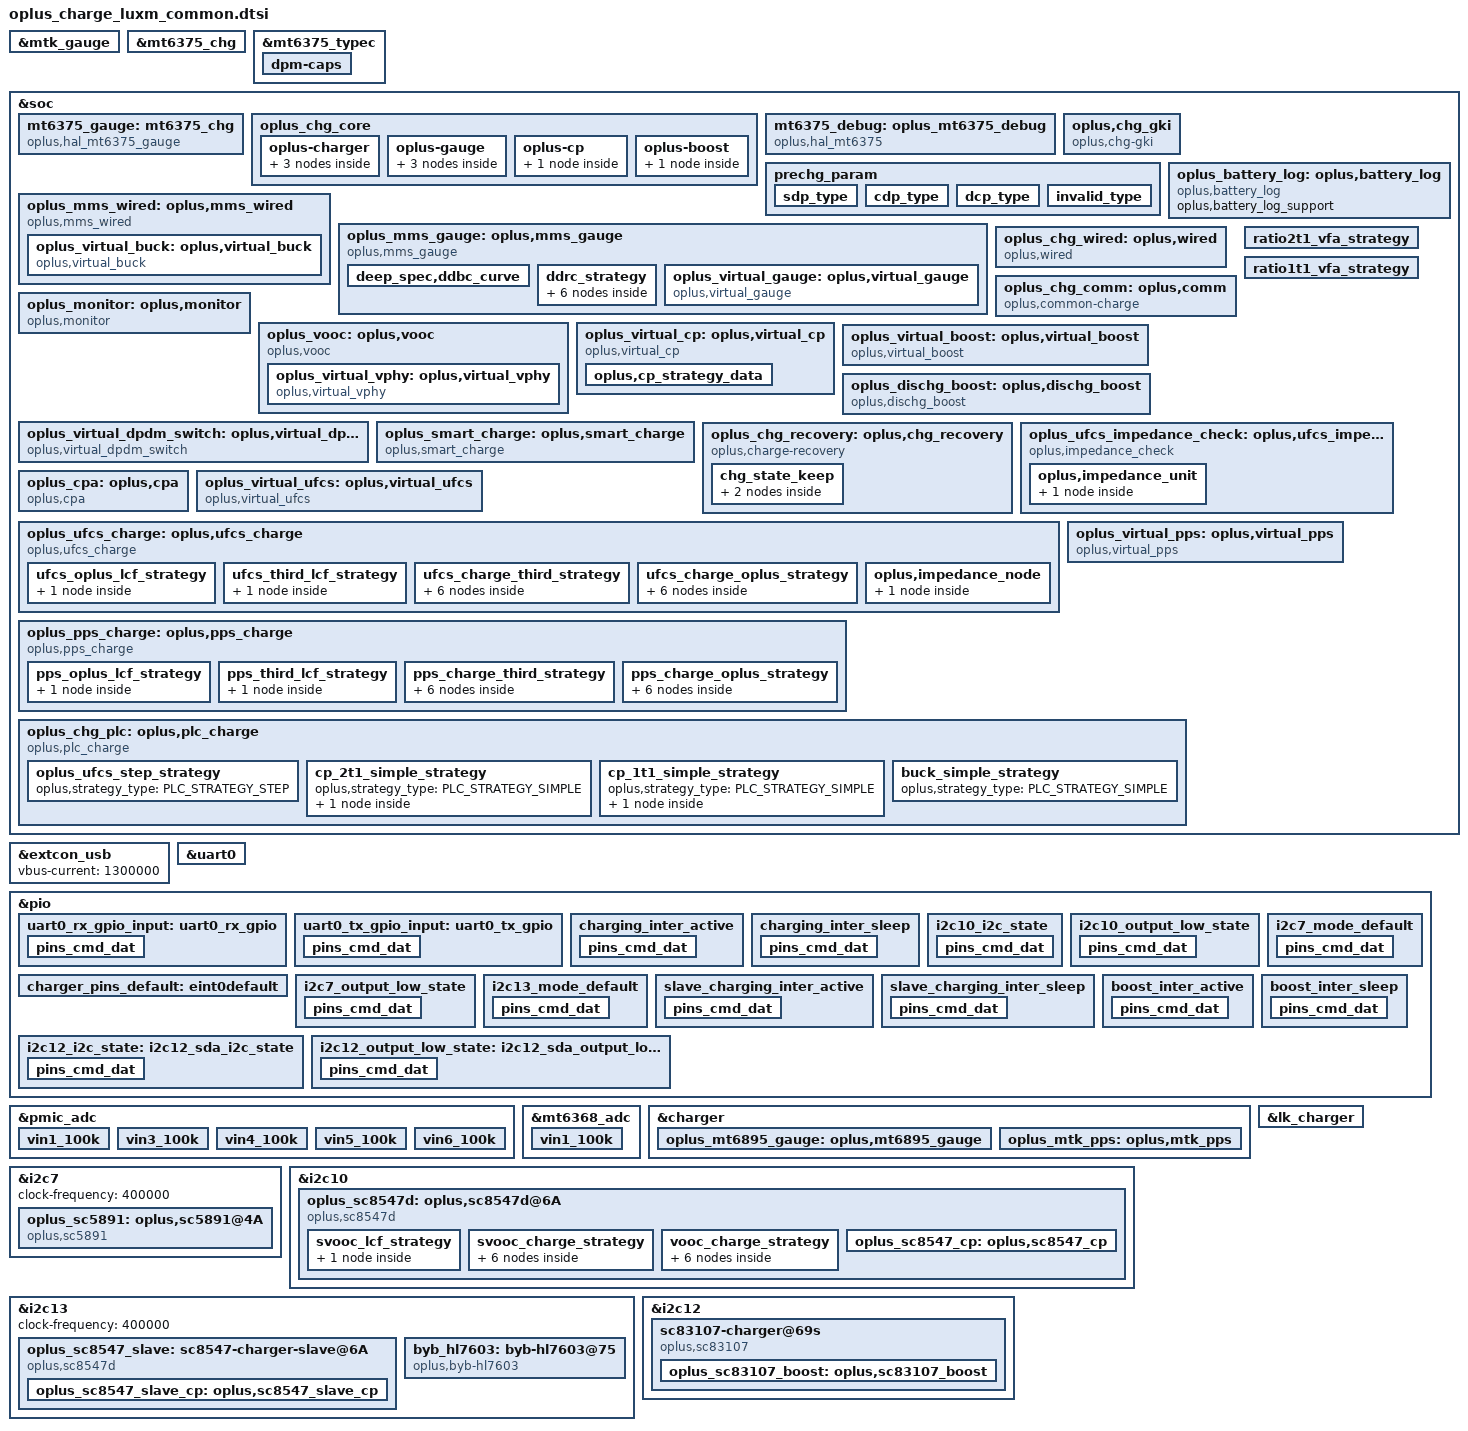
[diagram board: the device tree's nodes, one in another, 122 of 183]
// SPDX-License-Identifier: GPL-2.0-only
/*
* Copyright (C) 2025 Oplus. All rights reserved.
*/
#include <dt-bindings/iio/mt635x-auxadc.h>
#include <dt-bindings/pinctrl/mt6373-pinfunc.h>
#include <dt-bindings/pinctrl/mt65xx.h>
#include <dt-bindings/mfd/mt6375.h>
#include <dt-bindings/iio/adc/mediatek,mt6375_auxadc.h>
#include <dt-bindings/iio/adc/mediatek,mt6375_adc.h>
#include "oplus_chg.h"

&mtk_gauge {
	status = "okay";
	charger = <&mt6375_chg>;
	FUELGAGUE_APPLY = <(1)>;
	IS_SUBBOARD_TEMP_SUPPORT = <(0)>;
	EXTERNAL_AUTHENTICATE =<(1)>;
	Enable_Is_Force_Full = <(1)>;

	active-table = <(5)>;
	r-fg-value = <(1)>; /* R_sense resistance. evb1 use 2; evb2 and later use 1 milliohm */
	com-r-fg-value = <(0)>; /* R_sense compensate resistance. not use COM_R_FG_VALUE */
	RBAT_PULL_DOWN_R = <(24000)>;
	RBAT_PULL_UP_R = <(12000)>;
	RBAT_PULL_UP_VOLT = <(2800)>;
	USE_MORE_PRECISE_NTC_TABLE = <(1)>;
	car-tune-value = <(100)>;
	BAT_VOLTAGE_LOW_BOUND =  <(2750)>;
	LOW_TMP_BAT_VOLTAGE_LOW_BOUND =  <(2850)>;
	SHUTDOWN_GAUGE1_VBAT = <(27500)>;
	shutdown-gauge0-voltage = <(27500)>;
	VBAT2_DET_VOLTAGE1 = <(28000)>;
	VBAT2_DET_VOLTAGE2 = <(26000)>;
	VBAT2_DET_VOLTAGE3 = <(28500)>;
	SHUTDOWN_1_TIME = <(60)>;
	DIM2_TABLE_DISTINGUISH = <(1)>;
	AGING_FACTOR_MIN = <(75)>;
	BAT_BH_EN = <(1)>;
	keep-100-percent-minsoc = <(9500)>;
	aging-factor-diff = <(1)>;
	keep-100-percent = <(2)>;

	/* compensate The resistance of PCB */
	com-fg-meter-resistance = <(-20)>;
	#include "bat_setting/mt6899_battery_prop_dim2_ext_luxm.dtsi"
	#include "bat_setting/mt6899_battery_table_luxm.dtsi"
};

&mt6375_chg {
	interrupts = <MT6375_FL_PWR_RDY>, <MT6375_FL_DETACH>,
				<MT6375_FL_VBUS_OV>, <MT6375_FL_CHG_TOUT>,
				<MT6375_FL_WDT>, <MT6375_FL_BC12_DN>,
				<MT6375_INT_CHRDET_EXT>,
				<MT6375_FL_AICC_DONE>, <MT6375_FL_PE_DONE>,
				<MT6375_FL_BATPRO_DONE>,
				<MT6375_ADC_VBAT_MON_OV>,
				<MT6375_USBID_EVT>;
	interrupt-names = "fl_pwr_rdy", "fl_detach",
				"fl_vbus_ov", "fl_chg_tout",
				"fl_wdt", "fl_bc12_dn",
				"int_chrdet_ext",
				"fl_aicc_done", "fl_pe_done",
				"fl_batpro_done", "adc_vbat_mon_ov",
				"usbid_evt";
};

&mt6375_typec {
	/* 0: Unknown, 1: SNK, 2: SRC, 3: DRP, 4: Try.SRC, 5: Try.SNK */
	tcpc,role-def = <1>;
	/* 0: Default, 1: 1.5, 2: 3.0 */
	tcpc,rp-level = <0>;

	tcpc,en-floatgnd;
	wd,wd0-tsleep = <0>; /* add for wd0 */

	dpm-caps {
		attempt-discover-cable;
		/* BSP.CHG.Basic add for pd_svooc */
		/* add for tcpc */
		attempt-discover-id;
		attempt-discover-svids;
	};
};

&soc {
	mt6375_gauge: mt6375_chg {
		status = "okay";
		compatible = "oplus,hal_mt6375_gauge";

		oplus,ic_type = <OPLUS_CHG_IC_GAUGE>;
		oplus,ic_index = <1>;
		oplus,batt_num = <1>;
		oplus,mtk_gauge_power_sel_support;
		oplus,mtk_gauge_cali_track_support;
		oplus,mtk_gauge_power_sel_by_power_support;
		/* graphite sub btb valid temperature range, which is provided by hardware engineer. */
		oplus,sub_btb_valid_temp = <(-350) 1000>;

		oplus,vbatt_full_cv = <44500>;
		oplus,term_vol_temp_range = <350 200 100 0 (-100)>;
		oplus,term_vol_base = <27500 27500 27500 29000 30000 30000>;
	};
};

&extcon_usb {
	vbus-current = <1300000>;
};

&uart0 {
	pinctrl-names = "uart0_rx_gpio", "uart0_tx_gpio";
	pinctrl-0 = <&uart0_rx_gpio_input>;
	pinctrl-1 = <&uart0_tx_gpio_input>;
	status = "okay";
	txpin = <207>;
	rxpin = <208>;
};

&pio {
	uart0_rx_gpio_input: uart0_rx_gpio {
		pins_cmd_dat {
			pinmux = <PINMUX_GPIO208__FUNC_GPIO208>; /* URXD0 */
			input-enable;
			bias-disable;
		};
	};

	uart0_tx_gpio_input: uart0_tx_gpio {
		pins_cmd_dat {
			pinmux = <PINMUX_GPIO207__FUNC_GPIO207>; /* UTXD0 */
			input-enable;
			bias-disable;
		};
	};
};

&pmic_adc {
	vin1_100k {
		channel = <AUXADC_VIN1>;
		pures = <ADC_PURES_100K>;
	};
	vin3_100k {
		channel = <AUXADC_VIN3>;
		pures = <ADC_PURES_100K>;
	};
	vin4_100k {
		channel = <AUXADC_VIN4>;
		pures = <ADC_PURES_100K>;
	};
	vin5_100k {
		channel = <AUXADC_VIN5>;
		pures = <ADC_PURES_100K>;
	};
	vin6_100k {
		channel = <AUXADC_VIN6>;
		pures = <ADC_PURES_100K>;
	};
};

&mt6368_adc {
	vin1_100k {
		channel = <AUXADC_VIN1>;
		pures = <ADC_PURES_100K>;
	};
};

&pio {
	charging_inter_active: charging_inter_active {
		pins_cmd_dat {
			pinmux = <PINMUX_GPIO40__FUNC_GPIO40>;
			input-enable;
			bias-pull-up;
		};
	};

	charging_inter_sleep: charging_inter_sleep {
		pins_cmd_dat {
			pinmux = <PINMUX_GPIO40__FUNC_GPIO40>;
			input-enable;
			bias-pull-up;
		};
	};

	i2c10_i2c_state: i2c10_i2c_state {
		pins_cmd_dat {
			pinmux = <PINMUX_GPIO33__FUNC_SCL10>,
				 <PINMUX_GPIO34__FUNC_SDA10>;
			bias-disable;
		};
	};

	i2c10_output_low_state: i2c10_output_low_state {
		pins_cmd_dat {
			pinmux = <PINMUX_GPIO33__FUNC_GPIO33>,
				 <PINMUX_GPIO34__FUNC_GPIO34>;
			output-low;
		};
	};

	charger_pins_default: eint0default {
	};
};

&soc {
	oplus_chg_core {
		oplus,chg_framework_v2;
		oplus,smart_charging_screenoff;
		oplus,chg_spec_version = <OPLUS_CHG_SPEC_VER_V3P7_1>;
		oplus,common-charge-icl-support;

		oplus-charger {
			mtk_6895_groups: oplus,mtk_6895-groups {
				functions = <
					OPLUS_IC_FUNC_INIT
					OPLUS_IC_FUNC_EXIT
					OPLUS_IC_FUNC_REG_DUMP
					OPLUS_IC_FUNC_SMT_TEST
					OPLUS_IC_FUNC_BUCK_INPUT_PRESENT
					OPLUS_IC_FUNC_BUCK_INPUT_SUSPEND
					OPLUS_IC_FUNC_BUCK_INPUT_IS_SUSPEND
					OPLUS_IC_FUNC_BUCK_OUTPUT_SUSPEND
					OPLUS_IC_FUNC_BUCK_OUTPUT_IS_SUSPEND
					OPLUS_IC_FUNC_BUCK_SET_ICL
					OPLUS_IC_FUNC_BUCK_GET_ICL
					OPLUS_IC_FUNC_BUCK_SET_FCC
					OPLUS_IC_FUNC_BUCK_SET_FV
					OPLUS_IC_FUNC_BUCK_SET_ITERM
					OPLUS_IC_FUNC_BUCK_GET_INPUT_CURR
					OPLUS_IC_FUNC_BUCK_GET_INPUT_VOL
					OPLUS_IC_FUNC_OTG_BOOST_ENABLE
					OPLUS_IC_FUNC_BUCK_GET_CC_ORIENTATION
					OPLUS_IC_FUNC_BUCK_GET_CHARGER_TYPE
					OPLUS_IC_FUNC_BUCK_RERUN_BC12
					OPLUS_IC_FUNC_BUCK_QC_DETECT_ENABLE
					OPLUS_IC_FUNC_BUCK_SET_QC_CONFIG
					OPLUS_IC_FUNC_BUCK_SET_PD_CONFIG
					OPLUS_IC_FUNC_GET_SHUTDOWN_SOC
					OPLUS_IC_FUNC_BACKUP_SOC
					OPLUS_IC_FUNC_GET_TYPEC_MODE
					OPLUS_IC_FUNC_SET_TYPEC_MODE
					OPLUS_IC_FUNC_GET_TYPEC_ROLE
					OPLUS_IC_FUNC_GET_OTG_ENABLE
					OPLUS_IC_FUNC_BUCK_GET_HW_DETECT
					OPLUS_IC_FUNC_SET_USB_DISCHG_ENABLE
					OPLUS_IC_FUNC_GET_USB_DISCHG_STATUS
					OPLUS_IC_FUNC_IS_OPLUS_SVID
					OPLUS_IC_FUNC_BUCK_GET_USB_BTB_TEMP
					OPLUS_IC_FUNC_BUCK_GET_BATT_BTB_TEMP
					OPLUS_IC_FUNC_BUCK_SHIPMODE_ENABLE
					OPLUS_IC_FUNC_BUCK_SET_AICL_POINT
					OPLUS_IC_FUNC_SET_OTG_BOOST_CURR_LIMIT
					OPLUS_IC_FUNC_SET_OTG_BOOST_VOL
					OPLUS_IC_FUNC_BUCK_GET_FV
					OPLUS_IC_FUNC_BUCK_GET_TYPEC_STATE
					OPLUS_IC_FUNC_BUCK_DIS_INSERT_DETECT
					OPLUS_IC_FUNC_BUCK_GET_USB_AICL_ENHANCE
					OPLUS_IC_FUNC_BUCK_GET_LPD_INFO
					OPLUS_IC_FUNC_BUCK_GET_VBAT_PWR
				>;
				virqs = <
					OPLUS_IC_VIRQ_ERR
					OPLUS_IC_VIRQ_CC_DETECT
					OPLUS_IC_VIRQ_PLUGIN
					OPLUS_IC_VIRQ_CC_CHANGED
					OPLUS_IC_VIRQ_CHG_TYPE_CHANGE
					OPLUS_IC_VIRQ_OTG_ENABLE
					OPLUS_IC_VIRQ_SVID
					OPLUS_IC_VIRQ_TYPEC_STATE
				>;
			};

			mt6375_debug_groups: oplus,mt6375_debug_groups {
				functions = <
					OPLUS_IC_FUNC_INIT
					OPLUS_IC_FUNC_EXIT
				>;
				virqs = <
					OPLUS_IC_VIRQ_ERR
				>;
			};

			byb_hl7603_groups: oplus,byb-hl7603-groups {
				functions = <
					OPLUS_IC_FUNC_INIT
					OPLUS_IC_FUNC_EXIT
					OPLUS_IC_FUNC_REG_DUMP
					OPLUS_IC_FUNC_BUCK_GET_BYB_STATUS
					OPLUS_IC_FUNC_BUCK_GET_BYB_VOUT
					OPLUS_IC_FUNC_BUCK_SET_BYB_VOUT
				>;
				virqs = <
					OPLUS_IC_VIRQ_ERR
				>;
			};
		};

		oplus-gauge {
			mt6375_gauge_groups: oplus,mt6375_gauge_groups {
				functions = <
					OPLUS_IC_FUNC_INIT
					OPLUS_IC_FUNC_EXIT
					OPLUS_IC_FUNC_REG_DUMP
					OPLUS_IC_FUNC_SMT_TEST
					OPLUS_IC_FUNC_GAUGE_GET_BATT_VOL
					OPLUS_IC_FUNC_GAUGE_GET_BATT_MAX
					OPLUS_IC_FUNC_GAUGE_GET_BATT_MIN
					OPLUS_IC_FUNC_GAUGE_GET_BATT_CURR
					OPLUS_IC_FUNC_GAUGE_GET_BATT_TEMP
					OPLUS_IC_FUNC_GAUGE_GET_BATT_SOC
					OPLUS_IC_FUNC_GAUGE_GET_BATT_FCC
					OPLUS_IC_FUNC_GAUGE_GET_BATT_CC
					OPLUS_IC_FUNC_GAUGE_GET_BATT_RM
					OPLUS_IC_FUNC_GAUGE_GET_BATT_SOH
					OPLUS_IC_FUNC_GAUGE_GET_BATT_AUTH
					OPLUS_IC_FUNC_GAUGE_SET_BATT_FULL
					OPLUS_IC_FUNC_GAUGE_UPDATE_DOD0
					OPLUS_IC_FUNC_GAUGE_UPDATE_SOC_SMOOTH
					OPLUS_IC_FUNC_GAUGE_GET_CB_STATUS
					OPLUS_IC_FUNC_GAUGE_GET_BATT_NUM
					OPLUS_IC_FUNC_GAUGE_GET_DEVICE_TYPE
					OPLUS_IC_FUNC_GAUGE_GET_DEVICE_TYPE_FOR_VOOC
					OPLUS_IC_FUNC_GAUGE_GET_BATT_FCC
					OPLUS_IC_FUNC_GAUGE_GET_BATT_FC
					OPLUS_IC_FUNC_GAUGE_GET_BATT_QM
					OPLUS_IC_FUNC_GAUGE_GET_BATT_PD
					OPLUS_IC_FUNC_GAUGE_GET_BATT_RCU
					OPLUS_IC_FUNC_GAUGE_GET_BATT_RCF
					OPLUS_IC_FUNC_GAUGE_GET_BATT_FCU
					OPLUS_IC_FUNC_GAUGE_GET_BATT_FCF
					OPLUS_IC_FUNC_GAUGE_GET_BATT_SOU
					OPLUS_IC_FUNC_GAUGE_GET_BATT_DO0
					OPLUS_IC_FUNC_GAUGE_GET_BATT_DOE
					OPLUS_IC_FUNC_GAUGE_GET_BATT_TRM
					OPLUS_IC_FUNC_GAUGE_GET_BATT_PC
					OPLUS_IC_FUNC_GAUGE_GET_BATT_QS
					OPLUS_IC_FUNC_GAUGE_IS_SUSPEND
					OPLUS_IC_FUNC_GAUGE_GET_BCC_PARMS
					OPLUS_IC_FUNC_GAUGE_FASTCHG_UPDATE_BCC_PARMS
					OPLUS_IC_FUNC_GAUGE_GET_PREV_BCC_PARMS
					OPLUS_IC_FUNC_GAUGE_SET_BCC_PARMS
					OPLUS_IC_FUNC_GAUGE_SET_PROTECT_CHECK
					OPLUS_IC_FUNC_GAUGE_GET_AFI_UPDATE_DONE
					OPLUS_IC_FUNC_GAUGE_CHECK_RESET
					OPLUS_IC_FUNC_GAUGE_GET_DEVICE_TYPE_FOR_BCC
					OPLUS_IC_FUNC_GAUGE_SET_RESET_GAUGE_DATE
					OPLUS_IC_FUNC_GAUGE_GET_DOD0
					OPLUS_IC_FUNC_GAUGE_GET_DOD0_PASSED_Q
					OPLUS_IC_FUNC_GAUGE_GET_QMAX
					OPLUS_IC_FUNC_GAUGE_GET_QMAX_PASSED_Q
					OPLUS_IC_FUNC_GAUGE_SET_BATTERY_CURVE
					OPLUS_IC_FUNC_GAUGE_GET_GAUGE_CAR_C
					OPLUS_IC_FUNC_GAUGE_GET_SUB_BTB_CONNECT_STATE
					OPLUS_IC_FUNC_GAUGE_GET_GAUGE_TYPE
					OPLUS_IC_FUNC_GAUGE_GET_DEC_FG_TYPE
					OPLUS_IC_FUNC_GAUGE_SET_VCT
					OPLUS_IC_FUNC_GAUGE_SYNC_PLUGIN
					OPLUS_IC_FUNC_GAUGE_SET_DEEP_TERM_VOLT
				>;
				virqs = <
					OPLUS_IC_VIRQ_ERR
					OPLUS_IC_VIRQ_OFFLINE
					OPLUS_IC_VIRQ_RESUME
				>;
			};

			mt6895_gauge_groups: oplus,mt6895_gauge_groups {
				functions = <
					OPLUS_IC_FUNC_INIT
					OPLUS_IC_FUNC_EXIT
					OPLUS_IC_FUNC_GAUGE_GET_SUBBOARD_TEMP
				>;
				virqs = <
					OPLUS_IC_VIRQ_ERR
				>;
			};

			sc5891_gauge_groups: oplus,sc5891_gauge_groups {
				functions = <
					OPLUS_IC_FUNC_INIT
					OPLUS_IC_FUNC_EXIT
					OPLUS_IC_FUNC_GAUGE_GET_BATT_HMAC
					OPLUS_IC_FUNC_GAUGE_SEC_GET_ROMID
					OPLUS_IC_FUNC_GAUGE_SEC_WRITE_PAGE
					OPLUS_IC_FUNC_GAUGE_SEC_READ_PAGE
					OPLUS_IC_FUNC_GAUGE_SEC_ECDSA
					OPLUS_IC_FUNC_GAUGE_SEC_ECW
					OPLUS_IC_FUNC_GAUGE_SEC_SHUTDOWN
					OPLUS_IC_FUNC_GAUGE_SET_VCT
					OPLUS_IC_FUNC_GAUGE_GET_VCT
					OPLUS_IC_FUNC_GAUGE_GET_DEEP_DISCHG_COUNT
					OPLUS_IC_FUNC_GAUGE_SET_DEEP_DISCHG_COUNT
					OPLUS_IC_FUNC_GAUGE_SET_LAST_CC
					OPLUS_IC_FUNC_GAUGE_GET_LAST_CC
					OPLUS_IC_FUNC_GAUGE_SET_DEEP_TERM_VOLT
					OPLUS_IC_FUNC_GAUGE_GET_DEEP_TERM_VOLT
					OPLUS_IC_FUNC_GAUGE_GET_BATT_AUTH
					OPLUS_IC_FUNC_GAUGE_SEC_SET_PRIKEY
					OPLUS_IC_FUNC_GAUGE_SEC_GET_PRIKEY_INDEX
					OPLUS_IC_FUNC_GAUGE_GET_BATT_SN
					OPLUS_IC_FUNC_GAUGE_GET_SN_MATCH
					OPLUS_IC_FUNC_GAUGE_GET_BATT_HISTSOH_DATA
					OPLUS_IC_FUNC_GAUGE_SET_BATT_HISTSOH_DATA
					OPLUS_IC_FUNC_GAUGE_GET_BATT_IC_SN
					OPLUS_IC_FUNC_GAUGE_GET_DEC_CV_SOH
				>;
				virqs = <
					OPLUS_IC_VIRQ_ERR
				>;
			};
		};

		oplus-cp {
			sc8547_cp_groups: oplus,cp_groups {
			functions = <
					OPLUS_IC_FUNC_INIT
					OPLUS_IC_FUNC_EXIT
					OPLUS_IC_FUNC_REG_DUMP
					OPLUS_IC_FUNC_SMT_TEST
					OPLUS_IC_FUNC_CP_ENABLE
					OPLUS_IC_FUNC_CP_HW_INTI
					OPLUS_IC_FUNC_CP_SET_WORK_START
					OPLUS_IC_FUNC_CP_CHECK_WORK_MODE_SUPPORT
					OPLUS_IC_FUNC_CP_SET_WORK_MODE
					OPLUS_IC_FUNC_CP_GET_WORK_MODE
					OPLUS_IC_FUNC_CP_GET_VIN
					OPLUS_IC_FUNC_CP_GET_IIN
					OPLUS_IC_FUNC_CP_SET_IIN
					OPLUS_IC_FUNC_CP_GET_VOUT
					OPLUS_IC_FUNC_CP_GET_IOUT
					OPLUS_IC_FUNC_CP_GET_VAC
					OPLUS_IC_FUNC_CP_GET_WORK_STATUS
					OPLUS_IC_FUNC_CP_SET_ADC_ENABLE
					OPLUS_IC_FUNC_CP_WATCHDOG_ENABLE
					OPLUS_IC_FUNC_CP_SET_UCP_DISABLE
					OPLUS_IC_FUNC_CP_GET_IIN_MAX
					OPLUS_IC_FUNC_CP_WATCHDOG_RESET
					OPLUS_IC_FUNC_CP_SET_SSTIMEOUT_UCP_ENABLE
				>;
				virqs = <
					OPLUS_IC_VIRQ_ERR
					OPLUS_IC_VIRQ_ONLINE
					OPLUS_IC_VIRQ_OFFLINE
				>;
			};
		};

		oplus-boost {
			sc83107_boost_groups: oplus,boost_groups {
				functions = <
					OPLUS_IC_FUNC_INIT
					OPLUS_IC_FUNC_EXIT
					OPLUS_IC_FUNC_REG_DUMP
					OPLUS_IC_FUNC_SMT_TEST
					OPLUS_IC_FUNC_BOOST_SET_CV
					OPLUS_IC_FUNC_BOOST_ENABLE_OTG_MODE
					OPLUS_IC_FUNC_BOOST_SET_WORK_MODE
					OPLUS_IC_FUNC_BOOST_SET_BCL_RATE
					OPLUS_IC_FUNC_BOOST_SET_BCL_VOL
					OPLUS_IC_FUNC_BOOST_GET_IN_CV_MODE
					OPLUS_IC_FUNC_BOOST_GET_CV
					OPLUS_IC_FUNC_BOOST_IS_SUSPEND
					OPLUS_IC_FUNC_BOOST_SET_SUSPEND_RESUME_CV
				>;
				virqs = <
					OPLUS_IC_VIRQ_ERR
					OPLUS_IC_VIRQ_ONLINE
					OPLUS_IC_VIRQ_OFFLINE
				>;
			};
		};
	};
};

&soc {
	mt6375_debug: oplus_mt6375_debug {
		status = "okay";
		compatible = "oplus,hal_mt6375";

		oplus,tcpc_name = "type_c_port0";

		oplus,ic_type = <OPLUS_CHG_IC_BUCK>;
		oplus,ic_index = <2>;
	};
};

&soc {
	oplus,chg_gki {
		compatible = "oplus,chg-gki";
	};
};

&charger {
	io-channels = <&mt6368_adc (ADC_PURES_100K_MASK | AUXADC_VIN1)>,
		      <&pmic_adc AUXADC_VIN5>,
		      <&pmic_adc AUXADC_VIN5>,
		      <&pmic_adc AUXADC_VIN6>,
		      <&pmic_adc AUXADC_VIN1>,
		      <&pmic_adc AUXADC_VIN5>,
		      <&pmic_adc AUXADC_VIN6>,
			  <&mt6375_adc MT6375_ADC_VBAT>;
	io-channel-names = "auxadc1-ntc_sub_bat_tem",
			   "auxadc5-chargeric_temp",
			   "auxadc5_batt_btb_temp",
			   "sub_bat_btb_temp",
			   "auxadc6_usb_btb_temp",
			   "master_cp_temp",
			   "slave_cp_temp",
			   "vbat_pwr_vol";

	pinctrl-names = "default";
	pinctrl-0 = <&charger_pins_default>;
	oplus,support_ntc_01c_precision;
	oplus,support_subboard_ntc;
	max_charger_voltage = <15000000>;
	/* ntc_resistance:100k internal_pull_up:100k voltage:1.84v */
	oplus,ntc_temp_volt_1840mv;

	oplus,usb_aicl_enhance;
	/* usbtemp dischg use pmic regulator to set vbus down */
	oplus,support_usbtemp_dischg_reg_configurable;
	oplus,usbtemp_dischg_reg_addr = <0x989>;
	oplus,usbtemp_dischg_reg_mask = <0x7>;
	oplus,usbtemp_dischg_enable = <0x2>;
	oplus,usbtemp_dischg_disable = <0x0>;
	oplus,low_batt_otg_boost_curr_ua = <500000>;
	oplus,ic_type = <OPLUS_CHG_IC_BUCK>;
	oplus,ic_index = <0>;

	oplus_mt6895_gauge: oplus,mt6895_gauge {
		oplus,ic_type = <OPLUS_CHG_IC_GAUGE>;
		oplus,ic_index = <2>;
	};

	oplus_mtk_pps: oplus,mtk_pps {
		oplus,ic_type = <OPLUS_CHG_IC_PPS>;
		oplus,ic_index = <0>;
	};
};

&soc {
	prechg_param:prechg_param {
		sdp_type {
			oplus,chg-type = <OPLUS_PRECHG_TYPE_SDP>;
			oplus,input-current-ma = <500>;
			oplus,temp-boundary-degc = <(-10) (-5) 0 5 12 16 35 45 53>;
			oplus,temp-hyst-degc = <2>;
			oplus,ichg-ma = <
				/*           <-10 <-5  <0   <5   <12  <16  <35  <45  <53  >=53 */
				/* stage0 */ 0    250  250  250  250  250  250  250  250  0
				/* stage1 */ 0    250  250  250  500  500  500  500  500  0
				/* stage2 */ 0    600  600  600  600  600  600  600  600  0
				/* stage3 */ 0    363  363  600  600  600  600  600  600  0
				/* stage4 */ 0    363  363  600  600  600  600  600  600  0
			>;
			oplus,stage-thd-mv = <
				/*                <-10 <-5  <0   <5   <12  <16  <35  <45  <53  >=53 */
				/* stage0 high */ 2500 2500 2500 2500 2500 2500 2500 2500 2500 2500
				/* stage1 high */ 2750 2750 2750 2750 2750 2750 2750 2750 2750 2750
				/* stage2 high */ 3980 3980 3980 4080 3980 4230 4080 4250 4080 4080
				/* stage3 high */ 4180 4180 4180 4180 4130 4430 4230 4380 4130 4130
			>;
			oplus,pre2fast-thd-mv = <
				/*           <-10 <-5  <0   <5   <12  <16  <35  <45  <53  >=53 */
				/* stage0 */ 3300 3300 3300 3300 3300 3300 3300 3300 3300 3300
				/* stage1 */ 2600 2600 2600 2600 2600 2600 2600 2600 2600 2600
				/* stage2 */ 2600 2600 2600 2600 2600 2600 2600 2600 2600 2600
				/* stage3 */ 2600 2600 2600 2600 2600 2600 2600 2600 2600 2600
				/* stage4 */ 2600 2600 2600 2600 2600 2600 2600 2600 2600 2600
			>;
		};
		cdp_type {
			oplus,chg-type = <OPLUS_PRECHG_TYPE_CDP>;
			oplus,input-current-ma = <1500>;
			oplus,temp-boundary-degc = <(-10) (-5) 0 5 12 16 35 45 53>;
			oplus,temp-hyst-degc = <2>;
			oplus,ichg-ma = <
				/*           <-10 <-5  <0   <5   <12  <16  <35  <45  <53  >=53 */
				/* stage0 */ 0    250  250  250  250  250  250  250  250  0
				/* stage1 */ 0    250  250  250  500  500  500  500  500  0
				/* stage2 */ 0    690  690  1380 1600 1600 1600 1600 1600 0
				/* stage3 */ 0    363  363  690  1600 1600 1600 1600 1600 0
				/* stage4 */ 0    363  363  690  1035 1380 1600 1600 1600 0
			>;
			oplus,stage-thd-mv = <
				/*                <-10 <-5  <0   <5   <12  <16  <35  <45  <53  >=53 */
				/* stage0 high */ 2500 2500 2500 2500 2500 2500 2500 2500 2500 2500
				/* stage1 high */ 2750 2750 2750 2750 2750 2750 2750 2750 2750 2750
				/* stage2 high */ 3980 3980 3980 4080 3980 4230 4080 4250 4080 4080
				/* stage3 high */ 4180 4180 4180 4180 4130 4430 4230 4380 4130 4130
			>;
			oplus,pre2fast-thd-mv = <
				/*           <-10 <-5  <0   <5   <12  <16  <35  <45  <53  >=53 */
				/* stage0 */ 3300 3300 3300 3300 3300 3300 3300 3300 3300 3300
				/* stage1 */ 2600 2600 2600 2600 2600 2600 2600 2600 2600 2600
				/* stage2 */ 2600 2600 2600 2600 2600 2600 2600 2600 2600 2600
				/* stage3 */ 2600 2600 2600 2600 2600 2600 2600 2600 2600 2600
				/* stage4 */ 2600 2600 2600 2600 2600 2600 2600 2600 2600 2600
			>;
		};
		dcp_type {
			oplus,chg-type = <OPLUS_PRECHG_TYPE_DCP>;
			oplus,input-current-ma = <2000>;
			oplus,temp-boundary-degc = <(-10) (-5) 0 5 12 16 35 45 53>;
			oplus,temp-hyst-degc = <2>;
			oplus,ichg-ma = <
				/*           <-10 <-5  <0   <5   <12  <16  <35  <45  <53  >=53 */
				/* stage0 */ 0    250  250  250  250  250  250  250  250  0
				/* stage1 */ 0    250  250  250  500  500  500  500  500  0
				/* stage2 */ 0    690  690  1380 2200 2200 2200 2200 2200 0
				/* stage3 */ 0    363  363  690  2200 2200 2200 2200 2200 0
				/* stage4 */ 0    363  363  690  1035 1380 2070 2200 2200 0
			>;
			oplus,stage-thd-mv = <
				/*                <-10 <-5  <0   <5   <12  <16  <35  <45  <53  >=53 */
				/* stage0 high */ 2500 2500 2500 2500 2500 2500 2500 2500 2500 2500
				/* stage1 high */ 2750 2750 2750 2750 2750 2750 2750 2750 2750 2750
				/* stage2 high */ 3980 3980 3980 4080 3980 4230 4080 4250 4080 4080
				/* stage3 high */ 4180 4180 4180 4180 4130 4430 4230 4380 4130 4130
			>;
			oplus,pre2fast-thd-mv = <
				/*           <-10 <-5  <0   <5   <12  <16  <35  <45  <53  >=53 */
				/* stage0 */ 3300 3300 3300 3300 3300 3300 3300 3300 3300 3300
				/* stage1 */ 2600 2600 2600 2600 2600 2600 2600 2600 2600 2600
				/* stage2 */ 2600 2600 2600 2600 2600 2600 2600 2600 2600 2600
				/* stage3 */ 2600 2600 2600 2600 2600 2600 2600 2600 2600 2600
				/* stage4 */ 2600 2600 2600 2600 2600 2600 2600 2600 2600 2600
			>;
		};
		invalid_type {
			oplus,chg-type = <OPLUS_PRECHG_TYPE_INVALID>;
			oplus,input-current-ma = <500>;
			oplus,temp-boundary-degc = <(-10) (-5) 0 5 12 16 35 45 53>;
			oplus,temp-hyst-degc = <2>;
			oplus,ichg-ma = <
				/*           <-10 <-5  <0   <5   <12  <16  <35  <45  <53  >=53 */
				/* stage0 */ 0    250  250  250  250  250  250  250  250  0
				/* stage1 */ 0    250  250  250  500  500  500  500  500  0
				/* stage2 */ 0    600  600  600  600  600  600  600  600  0
				/* stage3 */ 0    363  363  600  600  600  600  600  600  0
				/* stage4 */ 0    363  363  600  600  600  600  600  600  0
			>;
			oplus,stage-thd-mv = <
				/*                <-10 <-5  <0   <5   <12  <16  <35  <45  <53  >=53 */
				/* stage0 high */ 2500 2500 2500 2500 2500 2500 2500 2500 2500 2500
				/* stage1 high */ 2750 2750 2750 2750 2750 2750 2750 2750 2750 2750
				/* stage2 high */ 3980 3980 3980 4080 3980 4230 4080 4250 4080 4080
				/* stage3 high */ 4180 4180 4180 4180 4130 4430 4230 4380 4130 4130
			>;
			oplus,pre2fast-thd-mv = <
				/*           <-10 <-5  <0   <5   <12  <16  <35  <45  <53  >=53 */
				/* stage0 */ 3300 3300 3300 3300 3300 3300 3300 3300 3300 3300
				/* stage1 */ 2600 2600 2600 2600 2600 2600 2600 2600 2600 2600
				/* stage2 */ 2600 2600 2600 2600 2600 2600 2600 2600 2600 2600
				/* stage3 */ 2600 2600 2600 2600 2600 2600 2600 2600 2600 2600
				/* stage4 */ 2600 2600 2600 2600 2600 2600 2600 2600 2600 2600
			>;
		};
	};
};

&mt6375_chg {
	support_icl_optimization;
};

&lk_charger {
	en_vol_ctrl_vibrate = <3200>;
	read_vbat_from_cp;
	support_tuv_authentication;
	high-temp-scheme;
	support_icl_optimization;
	charger_no_wiress;
	support_battery_type = <8>;
	support_chg_time_cnt;
	support_chg_time_r;
	support_chg_track_r;
	data-gpio = <131>;
	//cpu-id = <7>;
	//key-id = <1>;
	oplus,batt_info = /bits/ 8 <0x36 0x31 0x31 0x33 0x30 0x33 0x30 0x30 0x30 0x33 0x34 0x38
				    0x36 0x31 0x31 0x33 0x30 0x33 0x30 0x30 0x30 0x33 0x34 0x39>;
	oplus,batt_resource_info = /bits/ 8 <0 0>;
	sub_board_temp_support;
	support_sili_sc5891;
	over_high_temp_thr = <60>;
	sub_board_adc_channel = <18>;		/* AUXADC_CHAN_VIN1 in LK, Use the MT6368 PMIC */
	sub_board_adc_pmic = <1>;		/* use the MT6368 Pmic, in lk2 it's name is "second_pmic_sdmadc" */
	sub_board_adc_pull_up_voltage = <1840>;
	sub_board_adc_pures = <0>;	/* config as SDMADC_100K */

	support_sdp_screenoff;
	sdp_screenon_voltage = <3250>;
	support_quickboot_charge;
	set_plat_vsysmin = <3400>;

	/* mt6899 start */
	led-brightness = <102>;
	/* mt6899, such as max_charger_voltage to max-charger-voltage */
	max-charger-voltage = <15000000>;
	boot-battery-voltage = <3400000>;
	usb-charger-current = <500000>;
	ac-charger-current = <2050000>;
	ac-charger-input-current = <1500000>;
	non-std-ac-charger-current = <750000>;
	charging-host-charger-current = <1500000>;
	ta-ac-charger-current = <1500000>;
	pd-charger-current = <500000>;
	/* mt6899 end */

	/* sc83107 start*/
	support_boost_sc83107;
	sc83107_i2c_id = <12>;
	sc83107_irq_gpio = <42>;
	/* sc83107 end*/

	/* for silicon battery */
	is_silicon_battery;
	max-term-voltage-mv = <3260>;
	min-term-voltage-mv = <2750>;
	dcp-boot-thd-inc-mv = <(-300)>;
	cdp-boot-thd-inc-mv = <(50)>;
	sdp-boot-thd-inc-mv = <(50)>;
	wls-boot-thd-inc-mv = <(50)>;
	nochg-boot-thd-inc-mv = <(50)>;
	max-boot-thd-mv = <(3360)>;
	min-boot-thd-mv = <(2950)>;
	dcp-max-boot-thd-mv = <(3310)>;
	dcp-min-boot-thd-mv = <(2850)>;
	prechg1-thd-mv = <2900>;
	prechg1-current-ma = <250>;
	temp-low-inc1 = <500>; /* < -20 */
	temp-low-inc2 = <500>; /* -20 ~ -10 */
	temp-low-inc3 = <500>; /* -10 ~ 0 */
	temp-low-inc4 = <100>; /* 0 ~ 20 */
	temp-low-inc5 = <0>; /* > 20 */
	/* silicon battery end */
	prechg_param = <&prechg_param>;
};

&soc {
	oplus_mms_wired: oplus,mms_wired {
		compatible = "oplus,mms_wired";
		oplus,buck_ic = <&oplus_virtual_buck>;
		oplus,voocphy_ic = <&oplus_virtual_vphy>;
		oplus,adc_info_name = "100k_1840mv";
		oplus_spec,usbtemp_batttemp_gap = <12>;
		high-temp-scheme;

		/* support for V2.0 usbtemp protect. */
		oplus,support_usbtemp_protect_v2;
		oplus_spec,usbtemp_batt_temp_low = <50>;
		oplus_spec,usbtemp_batt_temp_high = <50>;
		oplus_spec,usbtemp_batt_temp_over_hot = <60>;
		oplus_spec,usbtemp_ntc_temp_low = <57>;
		oplus_spec,usbtemp_ntc_temp_high = <69>;
		oplus_spec,usbtemp_temp_gap_low_with_batt_temp = <7>;
		oplus_spec,usbtemp_temp_gap_with_batt_temp_in_over_hot = <15>;
		oplus_spec,usbtemp_temp_gap_high_with_batt_temp = <12>;
		oplus_spec,usbtemp_temp_gap_low_without_batt_temp = <12>;
		oplus_spec,usbtemp_temp_gap_high_without_batt_temp = <24>;
		oplus_spec,usbtemp_rise_fast_temp_low = <3>;
		oplus_spec,usbtemp_rise_fast_temp_high = <3>;
		oplus_spec,usbtemp_rise_fast_temp_count_low = <30>;
		oplus_spec,usbtemp_rise_fast_temp_count_high = <20>;
		oplus_spec,usbtemp_cool_down_ntc_low = <54>;
		oplus_spec,usbtemp_cool_down_ntc_high = <65>;
		oplus_spec,usbtemp_cool_down_gap_low = <12>;
		oplus_spec,usbtemp_cool_down_gap_high = <20>;
		oplus_spec,usbtemp_cool_down_recover_ntc_low = <48>;
		oplus_spec,usbtemp_cool_down_recover_ntc_high = <60>;
		oplus_spec,usbtemp_cool_down_recover_gap_low = <6>;
		oplus_spec,usbtemp_cool_down_recover_gap_high = <15>;
		oplus_spec,lpd_support_status = <2>;
		oplus_spec,lpd_sbu_thr_mv = <320 480>;
		oplus_spec,lpd_sbu_pullup_thr_mv = <1600 2400>;

		oplus_virtual_buck: oplus,virtual_buck {
			compatible = "oplus,virtual_buck";
			oplus,buck_ic = <&charger &mt6375_debug &byb_hl7603>;
			oplus,buck_ic_index = <0 1 2>;
			oplus,buck_ic_current_ratio = <100 0 0>;
			oplus,buck_ic_connect = <OPLUS_CHG_IC_CONNECT_PARALLEL>;
			oplus,main_charger = <0>;
			oplus,buck_ic_func_group = <&mtk_6895_groups &mt6375_debug_groups &byb_hl7603_groups>;

			oplus,ic_type = <OPLUS_CHG_IC_VIRTUAL_BUCK>;
			oplus,ic_index = <0>;

			io-channels = <&pmic_adc AUXADC_VIN3>, <&pmic_adc AUXADC_VIN4>;
			io-channel-names = "usb_temp_adc_l", "usb_temp_adc_r";

			oplus,uart_tx-gpio = <&pio 207 0x00>;
			oplus,uart_rx-gpio = <&pio 208 0x00>;
		};
	};

	oplus_mms_gauge: oplus,mms_gauge {
		compatible = "oplus,mms_gauge";
		oplus,gauge_ic = <&oplus_virtual_gauge>;
		oplus,voocphy_ic = <&oplus_virtual_vphy>;
		oplus,topic-update-interval = <10000>;
		oplus,support_subboard_ntc;
		oplus,fcl_support;
		oplus,fcl_index = <1>;
		oplus,vb_offset = <0>;

		deep_spec,support;
		deep_spec,soc_boost_term_voltage_offset_mv = <0>;
		deep_spec,uv_thr = <2750>;
		deep_spec,count_thr = <50>;
		deep_spec,vbat_soc = <80>;
		deep_spec,count_step = <0 10 0
					350 12 1
					450 15 2
					530 20 3>;

		deep_spec,term_coeff = <2750 450 0
					2900 500 0
					3000 600 0
					3010 600 0
					3050 650 0
					3100 750 0
					3110 750 0
					3150 800 0
					3160 800 0
					3200 900 0
					3210 900 0
					3260 1000 0>;
		deep_spec,ddrc_strategy_name = "ddrc_curve_v2";
		deep_spec,volt_step = <20>;
		deep_spec,ddbc_curve {
			oplus,temp_type = <OPLUS_STRATEGY_USE_BATT_TEMP>;
			oplus,temp_range = <(-100) 0 200>;
			deep_spec,ddbc_temp_cold = <500 3250 5
						   10000 3200 2>;
			deep_spec,ddbc_temp_cool = <500 3250 5
						   10000 3200 2>;
			deep_spec,ddbc_temp_normal = <500 3250 5
						   10000 3200 2>;
			deep_spec,ddbc_temp_warm = <500 3250 5
						   10000 3200 2>;
		};
		ddrc_strategy {
			oplus,temp_type = <OPLUS_STRATEGY_USE_BATT_TEMP>;
			oplus,ratio_range = <20 30 50 70 90>;
			oplus,temp_range = <(-100) 0 100 200 350>;
			strategy_ratio_range_min { /* 0 ~ 0.2 */
				strategy_temp_0 =	<0 2753 3000 0
							300 2752 3100 1
							700 3010 3150 2
							1100 3061 3160 3
							1500 3111 3210 4
							1900 3161 3260 5>;
				strategy_temp_1 =	<0 2753 3000 0
							400 2751 3000 1
							900 3010 3150 2
							1400 3061 3160 3
							1900 3111 3210 4
							2400 3161 3260 5>;
				strategy_temp_2 =	<0 2754 2900 0
							400 2751 3000 1
							900 3010 3150 2
							1400 3061 3160 3
							1900 3111 3210 4
							2400 3161 3260 5>;
				strategy_temp_3 =	<0 2750 2750 0
							400 2754 2900 1
							900 3000 3010 2
							1400 3060 3110 3
							1900 3110 3160 4
							2400 3160 3210 5>;
				strategy_temp_4 =	<0 2750 2750 0
							400 2754 2900 1
							900 2910 3010 2
							1400 2910 3010 3
							1900 2910 3010 4
							2400 2910 3010 5>;
				strategy_temp_5 =	<0 2750 2750 0
							400 2754 2900 1
							900 2910 3010 2
							1400 2910 3010 3
							1900 2910 3010 4
							2400 2910 3010 5>;
			};
			strategy_ratio_range_low {
				strategy_temp_0 =	<0 2753 3000 0
							250 2752 3100 1
							550 3010 3150 2
							850 3110 3160 3
							1150 3160 3210 4
							1450 3210 3260 5>;
				strategy_temp_1 =	<0 2753 3000 0
							300 2751 3000 1
							700 3010 3150 2
							1100 3061 3160 3
							1500 3111 3210 4
							1900 3161 3260 5>;
				strategy_temp_2 =	<0 2754 2900 0
							300 2751 3000 1
							700 3010 3150 2
							1100 3061 3160 3
							1500 3111 3210 4
							1900 3161 3260 5>;
				strategy_temp_3 =	<0 2750 2750 0
							300 2754 2900 1
							700 3000 3010 2
							1100 3060 3110 3
							1500 3110 3160 4
							1900 3160 3210 5>;
				strategy_temp_4 =	<0 2750 2750 0
							300 2754 2900 1
							700 2910 3010 2
							1100 2910 3010 3
							1500 2910 3010 4
							1900 2910 3010 5>;
				strategy_temp_5 =	<0 2750 2750 0
							300 2754 2900 1
							700 2910 3010 2
							1100 2910 3010 3
							1500 2910 3010 4
							1900 2910 3010 5>;
			};
			strategy_ratio_range_mid_low {
				strategy_temp_0 =	<0 2753 3000 0
							100 2752 3100 1
							250 3010 3150 2
							400 3110 3160 3
							550 3160 3210 4
							700 3210 3260 5>;
				strategy_temp_1 =	<0 2753 3000 0
							100 2751 3000 1
							300 3010 3150 2
							600 3061 3160 3
							900 3111 3210 4
							1200 3161 3260 5>;
				strategy_temp_2 =	<0 2754 2900 0
							100 2751 3000 1
							300 3010 3150 2
							600 3061 3160 3
							900 3111 3210 4
							1200 3161 3260 5>;
				strategy_temp_3 =	<0 2750 2750 0
							100 2754 2900 1
							300 3000 3010 2
							600 3060 3110 3
							900 3110 3160 4
							1200 3160 3210 5>;
				strategy_temp_4 =	<0 2750 2750 0
							100 2754 2900 1
							300 3000 3010 2
							600 3050 3050 3
							900 3100 3100 4
							1200 3150 3150 5>;
				strategy_temp_5 =	<0 2750 2750 0
							100 2754 2900 1
							300 3000 3010 2
							600 3050 3050 3
							900 3100 3100 4
							1200 3150 3150 5>;
			};
			strategy_ratio_range_mid {
				strategy_temp_0 =	<0 2753 3000 0
							50  2752 3100 1
							150 3010 3150 2
							300 3110 3160 3
							450 3160 3210 4
							600 3210 3260 5>;
				strategy_temp_1 =	<0 2753 3000 0
							50  2751 3000 1
							150 3010 3150 2
							350 3061 3160 3
							550 3111 3210 4
							750 3161 3260 5>;
				strategy_temp_2 =	<0 2754 2900 0
							50  2751 3000 1
							150 3010 3150 2
							350 3061 3160 3
							550 3111 3210 4
							750 3161 3260 5>;
				strategy_temp_3 =	<0 2750 2750 0
							50  2754 2900 1
							150 3000 3010 2
							350 3060 3110 3
							550 3110 3160 4
							750 3160 3210 5>;
				strategy_temp_4 =	<0 2750 2750 0
							50  2754 2900 1
							150 3000 3010 2
							350 3050 3050 3
							550 3100 3100 4
							750 3150 3150 5>;
				strategy_temp_5 =	<0 2750 2750 0
							50  2754 2900 1
							150 3000 3010 2
							350 3050 3050 3
							550 3100 3100 4
							750 3150 3150 5>;
			};
			strategy_ratio_range_mid_high {
				strategy_temp_0 =	<0 2753 3000 0
							50  2752 3100 1
							150 3010 3150 2
							250 3110 3160 3
							350 3160 3210 4
							450 3210 3260 5>;
				strategy_temp_1 =	<0 2753 3000 0
							50  2751 3000 1
							150 3010 3150 2
							250 3061 3160 3
							350 3111 3210 4
							450 3161 3260 5>;
				strategy_temp_2 =	<0 2754 2900 0
							50  2751 3000 1
							150 3010 3150 2
							250 3061 3160 3
							350 3111 3210 4
							450 3161 3260 5>;
				strategy_temp_3 =	<0 2750 2750 0
							50  2754 2900 1
							150 3000 3010 2
							250 3060 3110 3
							350 3110 3160 4
							450 3160 3210 5>;
				strategy_temp_4 =	<0 2750 2750 0
							50  2754 2900 1
							150 3000 3010 2
							250 3100 3100 3
							350 3150 3150 4
							450 3200 3200 5>;
				strategy_temp_5 =	<0 2750 2750 0
							50  2754 2900 1
							150 3000 3010 2
							250 3100 3100 3
							350 3150 3150 4
							450 3200 3200 5>;
			};
			strategy_ratio_range_high {
				strategy_temp_0 =	<0 2753 3000 0
							50  2752 3100 1
							150 3010 3150 2
							250 3110 3160 3
							350 3160 3210 4
							450 3210 3260 5>;
				strategy_temp_1 =	<0 2753 3000 0
							50  2751 3000 1
							150 3010 3150 2
							250 3061 3160 3
							350 3111 3210 4
							450 3161 3260 5>;
				strategy_temp_2 =	<0 2754 2900 0
							50  2751 3000 1
							150 3010 3150 2
							250 3061 3160 3
							350 3111 3210 4
							450 3161 3260 5>;
				strategy_temp_3 =	<0 2750 2750 0
							50  2754 2900 1
							150 3000 3010 2
							250 3060 3110 3
							350 3110 3160 4
							450 3160 3210 5>;
				strategy_temp_4 =	<0 2750 2750 0
							50  2754 2900 1
							150 3000 3010 2
							250 3100 3100 3
							350 3150 3150 4
							450 3200 3200 5>;
				strategy_temp_5 =	<0 2750 2750 0
							50  2754 2900 1
							150 3000 3010 2
							250 3100 3100 3
							350 3150 3150 4
							450 3200 3200 5>;
			};
		};
		oplus_virtual_gauge: oplus,virtual_gauge {
			compatible = "oplus,virtual_gauge";
			oplus,gauge_ic = <&oplus_sc5891 &mt6375_gauge &oplus_mt6895_gauge>;
			oplus,gauge_ic_index = <0 1 2>;
			oplus,gauge_ic_func_group = <&sc5891_gauge_groups &mt6375_gauge_groups &mt6895_gauge_groups>;
			oplus,batt_capacity_mah = <7500>;
			oplus,ic_type = <OPLUS_CHG_IC_VIRTUAL_GAUGE>;
			oplus,ic_index = <0>;
		};
	};
};

&soc {
	oplus_battery_log: oplus,battery_log {
		compatible = "oplus,battery_log";
		oplus,battery_log_support;
	};

	oplus_chg_wired: oplus,wired {
		compatible = "oplus,wired";

		oplus,vooc-support;

		oplus_spec,vbatt_pdqc_to_5v_thr = <4500>;
		oplus_spec,vbatt_pdqc_to_9v_thr = <4500>;
		oplus_spec,pd-iclmax-ma = <1500>;
		oplus_spec,qc-iclmax-ma = <1500>;
		oplus_spec,non-standard-ibatmax-ma = <500>;
		oplus_spec,input-power-mw = <
			2500		/* OPLUS_WIRED_CHG_MODE_UNKNOWN */
			2500		/* OPLUS_WIRED_CHG_MODE_SDP */
			7500		/* OPLUS_WIRED_CHG_MODE_CDP */
			10000		/* OPLUS_WIRED_CHG_MODE_DCP */
			10000		/* OPLUS_WIRED_CHG_MODE_VOOC */
			13500		/* OPLUS_WIRED_CHG_MODE_QC */
			13500		/* OPLUS_WIRED_CHG_MODE_PD */
		>;
		oplus_spec,led_on-fccmax-ma = <0 690 690 1380 3300 3300 3300 3300 1000 0>;
		oplus_spec,fccmax-ma-lv = <
		/*      <-10 <-5  <0   <5   <12  <16  <35  <45  <53  >=53 */
			0    250  250  250  500  500  500  500  500  0	/* OPLUS_WIRED_CHG_MODE_UNKNOWN */
			0    250  250  250  500  500  500  500  500  0	/* OPLUS_WIRED_CHG_MODE_SDP */
			0    250  250  250  500  500  500  500  500  0	/* OPLUS_WIRED_CHG_MODE_CDP */
			0    250  250  250  500  500  500  500  500  0	/* OPLUS_WIRED_CHG_MODE_DCP */
			0    250  250  250  500  500  500  500  500  0	/* OPLUS_WIRED_CHG_MODE_VOOC */
			0    250  250  250  500  500  500  500  500  0	/* OPLUS_WIRED_CHG_MODE_QC */
			0    250  250  250  500  500  500  500  500  0	/* OPLUS_WIRED_CHG_MODE_PD */
		>;
		oplus_spec,fccmax-ma-lv1 = <
		/*      <-10 <-5  <0   <5   <12  <16  <35  <45  <53  >=53 */
			0    690  690  1380 2200 2200 2200 2200 2200 0	/* OPLUS_WIRED_CHG_MODE_UNKNOWN */
			0    600  600  600  600  600  600  600  600  0	/* OPLUS_WIRED_CHG_MODE_SDP */
			0    690  690  1380 1600 1600 1600 1600 1600 0	/* OPLUS_WIRED_CHG_MODE_CDP */
			0    690  690  1380 2200 2200 2200 2200 2200 0	/* OPLUS_WIRED_CHG_MODE_DCP */
			0    690  690  1380 2200 2200 2200 2200 2200 0	/* OPLUS_WIRED_CHG_MODE_VOOC */
			0    690  690  1380 3300 3300 3300 3300 3300 0	/* OPLUS_WIRED_CHG_MODE_QC */
			0    690  690  1380 3300 3300 3300 3300 3300 0	/* OPLUS_WIRED_CHG_MODE_PD */
		>;
		oplus_spec,fccmax-ma-lv2 = <
		/*      <-10 <-5  <0   <5   <12  <16  <35  <45  <53  >=53 */
			0    363  363  690  2200 2200 2200 2200 2200 0	/* OPLUS_WIRED_CHG_MODE_UNKNOWN */
			0    363  363  600  600  600  600  600  600  0	/* OPLUS_WIRED_CHG_MODE_SDP */
			0    363  363  690  1600 1600 1600 1600 1600 0	/* OPLUS_WIRED_CHG_MODE_CDP */
			0    363  363  690  2200 2200 2200 2200 2200 0	/* OPLUS_WIRED_CHG_MODE_DCP */
			0    363  363  690  2200 2200 2200 2200 2200 0	/* OPLUS_WIRED_CHG_MODE_VOOC */
			0    363  363  690  2277 2415 3300 3300 3300 0	/* OPLUS_WIRED_CHG_MODE_QC */
			0    363  363  690  2277 2415 3300 3300 3300 0	/* OPLUS_WIRED_CHG_MODE_PD */
		>;
		oplus_spec,fccmax-ma-hv = <
		/*      <-10 <-5  <0   <5   <12  <16  <35  <45  <53  >=53 */
			0    363  363  690  1035 1380 2070 2200 1000 0	/* OPLUS_WIRED_CHG_MODE_UNKNOWN */
			0    363  363  600  600  600  600  600  600  0	/* OPLUS_WIRED_CHG_MODE_SDP */
			0    363  363  690  1035 1380 1600 1600 1600 0	/* OPLUS_WIRED_CHG_MODE_CDP */
			0    363  363  690  1035 1380 2070 2200 2200 0	/* OPLUS_WIRED_CHG_MODE_DCP */
			0    363  363  690  1035 1380 2070 2200 2200 0	/* OPLUS_WIRED_CHG_MODE_VOOC */
			0    363  363  690  1035 1380 2070 3300 3300 0	/* OPLUS_WIRED_CHG_MODE_QC */
			0    363  363  690  1035 1380 2070 3300 3300 0	/* OPLUS_WIRED_CHG_MODE_PD */
		>;

		oplus_spec,cool_down_sale_pdqc_vol_mv = <5000>;
		oplus_spec,cool_down_sale_pdqc_curr_ma = <1200>;
		oplus_spec,cool_down_pdqc_vol_mv = <5000 5000 5000 9000 9000>;
		oplus_spec,cool_down_pdqc_curr_ma = <1200 1500 1500 1500 1500>;
		oplus_spec,cool_down_vooc_curr_ma = <1200 1500 2000 2500 3000 3000>;
		oplus_spec,cool_down_normal_curr_ma = <1200 1500 2000>;

		oplus_spec,vbus_ov_thr_mv = <11000 11000>;
		oplus_spec,vbus_uv_thr_mv = <4300 4300>;

		/* first data is strategy used temp type */
		oplus,pd_strategy_name = "cgcl";
		oplus,pd_strategy_data = <OPLUS_STRATEGY_USE_SHELL_TEMP
					    0   420 2000 1 0
					    410 430 1500 2 0
					    420 440 1200 2 1>;
		oplus,qc_strategy_name = "cgcl";
		oplus,qc_strategy_data = <OPLUS_STRATEGY_USE_SHELL_TEMP
					    0   420 2000 1 0
					    410 430 1500 2 0
					    420 440 1200 2 1>;
	};

	oplus_chg_comm: oplus,comm {
		compatible = "oplus,common-charge";
		oplus_spec,dec_step = <20>;
		oplus_spec,dec-vol-cc-full-thr = <0 200 400 600 800 1000>;
		oplus_spec,dec-vol-fv-full-mv = <0 20 40 40 60 60>;
		oplus_spec,dec-vol-vct-mv = <0 20 40 40 60 60>;
		oplus_spec,batt-them-thr = <(-100) (-50) 0 50 120 160 350 450 530>;
		oplus_spec,iterm-ma = <373>; /* 7265*0.05+10 */
		oplus_spec,removed_bat_decidegc = <390>; /*-39 degree*/
		oplus_spec,fv-mv = <4500 4500 4500 4500 4500 4500 4500 4485 4130 4130>;
		oplus_spec,sw-fv-mv = <4450 4450 4450 4450 4450 4450 4450 4435 4080 4080>;
		oplus_spec,hw-fv-inc-mv = <0 18 18 18 18 18 18 18 18 0>;
		oplus_spec,sw-over-fv-mv = <4510 4510 4510 4510 4510 4510 4510 4495 4140 4140>;
		oplus_spec,sw-over-fv-dec-mv = <8>;
		oplus_spec,non-standard-sw-fv-mv = <3930>;
		oplus_spec,non-standard-fv-mv = <3980>;
		oplus_spec,non-standard-hw-fv-inc-mv = <18>;
		oplus_spec,non-standard-sw-over-fv-mv = <3990>;
		oplus_spec,non-standard-vbatdet-mv = <3680>;
		oplus_spec,wired-vbatdet-mv = <0 4200 4200 4300 4400 4400 4400 4385 4030 0>;
		oplus_spec,fcc-gear-cnt = <4>;
		oplus_spec,fcc-gear-thr-mv = <
			/*                <-10 <-5  <0   <5   <12  <16  <35  <45  <53  >=53 */
			/* stage0 high */ 2750 2750 2750 2750 2750 2750 2750 2750 2750 2750
			/* stage1 high */ 3980 3980 3980 4100 3980 4230 4080 4250 4080 4080
			/* stage2 high */ 4180 4180 4180 4380 4130 4430 4230 4380 4130 4130
		>;
		oplus_spec,fcc-gear-shake-mv = <
			/*                <-10 <-5  <0   <5   <12  <16  <35  <45  <53  >=53 */
			/* stage0 high */ 100  100  100  100  100  100  100  100  100  100
			/* stage1 high */ 400  400  400  400  300  300  180  180  180  180
			/* stage2 high */ 400  400  400  400  300  300  180  180  180  180
		>;
		oplus_spec,vbatt-ov-thr-mv = <4600>;

		oplus_spec,full_pre_ffc_judge;
		oplus_spec,full-pre-ffc-mv = <4460>;
		oplus_spec,ffc-temp-thr = <120 210 350 440>;
		oplus_spec,wired-ffc-step-max = <2>;
		oplus_spec,wired-ffc-fv-mv = <4630 4630>;

		oplus_spec,wired-ffc-fv-cutoff-mv = <4545 4540 4500
						     4545 4525 4485>;
		oplus_spec,wired-ffc-fcc-ma = <1500 1500 1500
					       1250 1000 1000>;
		oplus_spec,wired-ffc-fcc-cutoff-ma = <1300 1300 1300
						      1150 900 900>;
		oplus_spec,drop_soc_2_temp_ladder = <(-50) 0 0 0 0 0 0 0 0 0>;
		oplus_spec,volt_diff_ladder_of_drop_soc_2 = <150 150 0 0 0 0 0 0 0 0>;
		oplus_spec,keep_soc_2_temp_ladder = <(-200) (-50) 0 0 0 0 0 0 0 0>;
		oplus_spec,volt_diff_ladder_of_keep_soc_2 = <80 90 100 0 0 0 0 0 0 0>;
		oplus_spec,keep_soc_3_temp_ladder = <(-200) (-50) 0 0 0 0 0 0 0 0>;
		oplus_spec,volt_diff_ladder_of_keep_soc_3 = <130 140 150 0 0 0 0 0 0 0>;
		oplus_spec,back_rm_of_drop_soc_2 = <37>;
		oplus_spec,back_rm_of_drop_soc_1 = <0>;
		oplus_spec,load_current_of_drop_soc_2 = <1500>;
		oplus_spec,load_current_of_drop_soc_1 = <2000>;
		oplus_spec,current_limit_of_drop_soc_2 = <700>;
		oplus_spec,volt_of_fast_drop_soc_1 = <2750>;
		oplus_spec,support_uisoc_low_battery_control;
		oplus_spec,soc_down_ladder = <2 11 60 95 100 0 0 0 0 0>;
		oplus_spec,soc_down_delay_hz_ladder = <20 20 40 60 150 300 0 0 0 0>;
		oplus_spec,soc_down_chg_delay_hz_ladder = <90 40 40 60 150 300 0 0 0 0>;
		oplus_spec,soc_down_default_delay_hz = <40>;
		oplus_spec,vbat_uv_thr_mv = <2750>;
		oplus_spec,vbat_charging_uv_thr_mv = <2750>;
		oplus,chg_shutdown_max_mv = <2750>;

		/*If use subboard NTC as battery temp, config it as 20, otherwise 0 */
		oplus_spec,tbatt_power_off_cali_temp = <0>;
		oplus,vooc_show_ui_soc_decimal;
		oplus_spec,poweroff_high_batt_temp = <720>;
		oplus_spec,poweroff_emergency_batt_temp = <770>;
		oplus,ui_soc_decimal_speedmin = <20>;
		oplus,gauge_stuck_jump_support;
		oplus,gauge_stuck_threshold = <15>;
		oplus,gauge_stuck_time = <50>;
		oplus,ui_soc_2_voltage_comp_mv = <30>;
		oplus,ui_soc_3_voltage_comp_mv = <100>;
		oplus_spec,support_boost_ic;
	};

	oplus_monitor: oplus,monitor {
		compatible = "oplus,monitor";
		oplus,topic-update-interval = <60000>;

		track,fast_chg_break_t_thd = <2500>;
		track,general_chg_break_t_thd = <200>;
		track,voocphy_type = <3>;
		track,wired_max_power = <80000>;
		track,wired_fast_chg_scheme = <2>;

		track,gauge_status_ctrl;
		track,external_gauge_num = <0>;
		track,low_soc_monitor_ctrl;

		track,track_ver = <TRACK_VER_4_0>;
	};

	ratio2t1_vfa_strategy: ratio2t1_vfa_strategy {
		oplus,fastchg_allow_min_vbat_mv = <2850>;
		oplus,fastchg_allow_first_vbat_mv = <3000>;
		oplus,fastchg_allow_over_margin_timeout_ms = <60000>;
	};

	ratio1t1_vfa_strategy: ratio1t1_vfa_strategy {
		oplus,fastchg_allow_min_vbat_mv = <3300>;
		oplus,fastchg_allow_first_vbat_mv = <3500>;
		oplus,fastchg_allow_over_margin_timeout_ms = <60000>;
	};

	oplus_vooc: oplus,vooc {
		compatible = "oplus,vooc";
		oplus,vooc_ic = <&oplus_virtual_vphy>;

		oplus_spec,vooc_soc_range = <55 75 85>;

		oplus,vooc_data_width = <7>;
		oplus,vooc_curr_max = <CP_CURR_LIMIT_7BIT_15_0A>; /* 80W: 11V 7.3A(IBUS *2) */
		oplus,vooc_power_max_w = <80>;
		oplus,vooc_project = <7>;
		oplus,vooc_curr_table_type = <VOOC_CP_CURR_TABLE>;
		oplus,voocphy_support = <3>; /* AP_DUAL_CP_VOOCPHY */
		oplus,support_fake_vooc_check;
		oplus,subboard_ntc_abnormal_current = <4000>;
		oplus,cp_cooldown_limit_percent_75 = <CP_CURR_LIMIT_7BIT_6_0A>;
		oplus,cp_cooldown_limit_percent_85 = <CP_CURR_LIMIT_7BIT_4_0A>;

		/* first data is strategy used temp type */
		oplus,general_strategy_name = "cgcl";
		oplus,general_strategy_data = < OPLUS_STRATEGY_USE_SHELL_TEMP
						0   385 CP_CURR_LIMIT_7BIT_15_0A 1 0
						375 395 CP_CURR_LIMIT_7BIT_12_6A 2 0
						385 420 CP_CURR_LIMIT_7BIT_8_0A 3 1
						410 440 CP_CURR_LIMIT_7BIT_6_0A 3 2 >;

		oplus,bypass_strategy_name = "cgcl";
		oplus,bypass_strategy_data = <OPLUS_STRATEGY_USE_SHELL_TEMP
						0   350 CP_CURR_LIMIT_7BIT_6_0A  1 0
						340 380 CP_CURR_LIMIT_7BIT_5_0A  2 0
						370 440 CP_CURR_LIMIT_7BIT_4_0A  2 1>;

		oplus,svooc_vfa_strategy = <&ratio2t1_vfa_strategy>;
		oplus,vooc_vfa_strategy = <&ratio1t1_vfa_strategy>;

		oplus,plc_strategy-data = <&buck_simple_strategy &cp_2t1_simple_strategy &cp_1t1_simple_strategy>;
		oplus,plc_strategy-names = "default", "svooc", "vooc";

		oplus_virtual_vphy: oplus,virtual_vphy {
			compatible = "oplus,virtual_vphy";
			oplus,vphy_ic = <&oplus_sc8547d>;
			oplus,dpdm_switch_ic = <&oplus_virtual_dpdm_switch>;

			oplus,ic_type = <OPLUS_CHG_IC_VIRTUAL_VPHY>;
			oplus,ic_index = <0>;
		};
	};

	oplus_virtual_cp: oplus,virtual_cp {
		compatible = "oplus,virtual_cp";

		oplus,ic_type = <OPLUS_CHG_IC_VIRTUAL_CP>;
		oplus,ic_index = <0>;

		oplus,cp_ic = <&oplus_sc8547_cp &oplus_sc8547_slave_cp>;
		oplus,input_curr_max_ma = <4000 4000>;

		oplus,cp_ic_connect = <OPLUS_CHG_IC_CONNECT_PARALLEL>;
		oplus,main_cp = <0>;

		oplus,reg_proc_node;
		oplus,cp_strategy = <CP_STRAT_OPEN_BY_CURR>;
		oplus,cp_strategy_data {
			oplus,cp_open_curr_thr_ma = <0 1900>;
			oplus,cp_close_curr_thr_ma = <0 1600>;
		};
	};

	oplus_virtual_boost: oplus,virtual_boost {
		compatible = "oplus,virtual_boost";
		oplus,boost_ic = <&oplus_sc83107_boost>;
		oplus,boost_ic_index = <0>;
		oplus,boost_ic_func_group = <&sc83107_boost_groups>;
		oplus,ic_func_group = <&sc83107_boost_groups>;

		oplus,ic_type = <OPLUS_CHG_IC_VIRTUAL_BOOST>;
		oplus,ic_index = <0>;
	};

	oplus_dischg_boost: oplus,dischg_boost {
		compatible = "oplus,dischg_boost";
		oplus,boost_ic = <&oplus_virtual_boost>;

		oplus_boost,ic_type = <HYBRID_BOOST>;
		oplus_boost,init-cv-mv = <3100>;
		oplus_boost,plugin-cv-mv = <3000>;
		oplus_boost,plugout-cv-mv = <3100>;
		oplus_boost,suspend-cv-mv = <3100>;
		oplus_boost,resume-cv-mv = <3100>;
		oplus_boost,normalchg-cv-mv = <3000>;
		oplus_boost,fastchg-cv-mv = <3000>;
		oplus_boost,boost-ratio = <116>;
	};

	oplus_virtual_dpdm_switch: oplus,virtual_dpdm_switch {
		compatible = "oplus,virtual_dpdm_switch";
		oplus,use_audio_switch;
		oplus,ic_type = <OPLUS_CHG_IC_MISC>;
		oplus,ic_index = <0>;
	};

	oplus_smart_charge: oplus,smart_charge {
		compatible = "oplus,smart_charge";
		oplus,smart_chg_soh_support;
		oplus,batt_sn_support;
	};

	oplus_chg_recovery: oplus,chg_recovery {
		compatible = "oplus,charge-recovery";

		chg_state_keep {
			wired_disconnect_detection {
				protocol_switch_table = <
					CHG_PROTOCOL_UFCS  44  3  3
					CHG_PROTOCOL_PPS    0  3  3
					CHG_PROTOCOL_VOOC   0  0  0
					CHG_PROTOCOL_PD     0  3  3
					CHG_PROTOCOL_QC     0  3  3
					CHG_PROTOCOL_BC12   0  3  3
				>;
			};
			vooc_disconnect_detection {};
		};
	};
};

&pio {
	i2c7_mode_default: i2c7_mode_default {
		pins_cmd_dat {
			pinmux = <PINMUX_GPIO152__FUNC_SDA7>,
				 <PINMUX_GPIO151__FUNC_SCL7>;
			bias-pull-up = <MTK_PULL_SET_RSEL_101>;
		};
	};

	i2c7_output_low_state: i2c7_output_low_state {
		pins_cmd_dat {
			pinmux = <PINMUX_GPIO151__FUNC_GPIO151>,
				 <PINMUX_GPIO152__FUNC_GPIO152>;
			output-low;
		};
	};
};

&i2c7 {
	status = "okay";
	clock-frequency = <400000>;

	oplus_sc5891: oplus,sc5891@4A {
		compatible = "oplus,sc5891";
		status = "okay";
		reg = <0x4A>;
		oplus,ic_type = <OPLUS_CHG_IC_GAUGE>;
		oplus,ic_index = <0>;

		oplus,i2c_scl-gpio = <&pio 151 0x00>;
		oplus,i2c_sda-gpio = <&pio 152 0x00>;
		oplus,prikey_index = <0>;
		oplus,sc5891_avoid = <1>;
		pinctrl-names = "default", "output-low-state";
		pinctrl-0 = <&i2c7_mode_default>;
		pinctrl-1 = <&i2c7_output_low_state>;

		/* TODO: Temporarily add serial numbers for both domestic and export batteries */
		oplus,batt_info = /bits/ 8 <0x36 0x31 0x31 0x33 0x30 0x33 0x30 0x30 0x30 0x33 0x34 0x38
					    0x36 0x31 0x31 0x33 0x30 0x33 0x30 0x30 0x30 0x33 0x34 0x39>;
	};
};

&i2c10 {
	status = "okay";
	clock-frequency = <400000>;
	mediatek,fifo-use-polling;
	oplus_sc8547d: oplus,sc8547d@6A {
		status = "okay";
		compatible = "oplus,sc8547d";
		reg = <0x6A>;

		oplus,use_vooc_phy;
		oplus,use_ufcs_phy;
		oplus_spec,irq_gpio = <&pio 40 0x00>;
		interrupt-parent = <&pio>;
		interrupts = <9 0>;

		pinctrl-names = "charging_inter_active", "charging_inter_sleep", "i2c-state", "output-low-state";
		pinctrl-0 = <&charging_inter_active>;
		pinctrl-1 = <&charging_inter_sleep>;
		pinctrl-2 = <&i2c10_i2c_state>;
		pinctrl-3 = <&i2c10_output_low_state>;

		oplus,ic_type = <OPLUS_CHG_IC_VPHY>;
		oplus,ic_index = <0>;
		oplus,vooc-version = <VOOC_VERSION_5_0>;

		ocp_reg = <0xe>;
		ovp_reg = <0x36>;/* vbat ovp 4.85v */
		vbus_ovp_reg = /bits/ 8 <0x5A>;  /* vbus ovp: 10.5v */
		oplus_spec,voocphy_dual_cp_support;
		oplus_spec,slave_cp_enable_thr = <1400>;		//2000-100mA
		oplus_spec,slave_cp_disable_thr_high = <1100>;	//1500+100mA
		oplus_spec,voocphy_current_default = <73>;
		oplus_spec,ap_control_allow;

		oplus_spec,svooc_cool_down_current_limit = <146 20 20 24 30 34 40 44 50 54 60 64 70 74>;
		oplus_spec,vooc_cool_down_current_limit = <73 20 20 24 30 34 40 44 50 54 60 64 70 74>;

		oplus_spec,vooc_low_temp = <50>;
		oplus_spec,vooc_little_cold_temp = <50>;
		oplus_spec,vooc_cool_temp = <120>;
		oplus_spec,vooc_little_cool_temp = <160>;
		oplus_spec,vooc_little_cool_high_temp = <210>;
		oplus_spec,vooc_normal_low_temp = <350>;
		oplus_spec,vooc_normal_high_temp = <440>;
		oplus_spec,vooc_high_temp = <500>;
		oplus_spec,vooc_over_high_temp = <510>;
		oplus_spec,vooc_strategy_normal_current = <122>;
		oplus_spec,vooc_normal_to_little_cool_current = <100>;
		oplus_spec,vooc_multistep_initial_batt_temp = <1000>;

		oplus_spec,vooc_low_soc = <0>;
		oplus_spec,vooc_high_soc = <90>;

		oplus_spec,vooc_warm_vol_thr = <4000>;
		oplus_spec,vooc_warm_soc_thr = <55>;
		oplus_spec,vooc_full_recheck_temp = <210>;

		oplus_spec,vooc_strategy1_batt_high_temp0 = <385>;
		oplus_spec,vooc_strategy1_batt_high_temp1 = <395>;
		oplus_spec,vooc_strategy1_batt_high_temp2 = <420>;
		oplus_spec,vooc_strategy1_batt_low_temp2 = <410>;
		oplus_spec,vooc_strategy1_batt_low_temp1 = <385>;
		oplus_spec,vooc_strategy1_batt_low_temp0 = <375>;

		oplus_spec,vooc_strategy1_high_current0 = <80>;
		oplus_spec,vooc_strategy1_high_current1 = <61>;
		oplus_spec,vooc_strategy1_high_current2 = <40>;
		oplus_spec,vooc_strategy1_low_current2 = <40>;
		oplus_spec,vooc_strategy1_low_current1 = <61>;
		oplus_spec,vooc_strategy1_low_current0 = <80>;

		oplus_spec,voocphy_freq_mincore = <925000>;
		oplus_spec,voocphy_freq_midcore = <1718000>;
		oplus_spec,voocphy_freq_maxcore = <1718000>;
		oplus_spec,voocphy_current_change_timeout = <100>;
		oplus_spec,copycat_vooc_support;
		oplus_spec,copycat_vooc_accuracy_value = <105>;

		oplus_spec,fastchg_timeout_time_init = <186810>;
		oplus_spec,voocphy_ibat_over_current = <16000>;
		oplus_spec,voocphy_svooc_cp_max_ibus = <4500>;
		oplus_spec,voocphy_vooc_cp_max_ibus = <4500>;
		oplus_spec,voocphy_cp_max_ibus = <4500>;

		oplus_spec,vooc_little_cold_full_voltage = <0>;
		oplus_spec,vooc_cool_full_voltage = <4130>;
		oplus_spec,vooc_little_cool_full_voltage = <4430>;
		oplus_spec,vooc_little_cool_high_full_voltage = <4550>;
		oplus_spec,vooc_warm_full_voltage = <4130>;
		oplus_spec,vooc_1time_full_voltage = <4560>;
		oplus_spec,vooc_ntime_full_voltage = <4550>;
		oplus_spec,soc_range = <0 20 35 55 75 85 90>;
		oplus_spec,full_voltage = < /* vol_1time vol_ntime */
					4160 4150 /* 0 ~ 5 */
					4140 4130 /* 5 ~ 12 */
					4440 4430 /* 12 ~ 16 */
					4560 4550 /* 16 ~ 20 */
					4560 4550 /* 20 ~ 35 */
					4560 4550 /* 35 ~ 44 */
					4140 4130 /* 44 ~ 51 */
					>;

		svooc_batt_sys_curve = <0 1 0 1 0 0 0	// 4000mA
					1 1 1 1 0 0 0	// 4604mV
					0 0 1 1 0 1 0	// 2600mA
					1 1 1 1 0 0 0	// 4604mV
					0 0 0 1 0 1 1	// 1100mA
					1 1 1 1 0 0 0>;	// 4604mV

		vooc_batt_sys_curve =  <0 1 0 1 0 0 0	// 4000mA
					1 1 1 1 0 0 0	// 4604mV
					0 0 1 1 0 1 0	// 2600mA
					1 1 1 1 0 0 0	// 4604mV
					0 0 0 1 0 1 1	// 1100mA
					1 1 1 1 0 0 0>;	// 4604mV

		svooc_lcf_strategy {
			oplus,temp_type = <OPLUS_STRATEGY_USE_SHELL_TEMP>;
			oplus,temp_range = <0 50 120 160 210 380 440>;

			strategy_temp_range_curves {
				strategy_temp_range_t0 =	<350 4500 0
								 325 4490 0
								 300 4480 0
								 275 4470 0
								 250 4460 1>;
				strategy_temp_range_t1 =	<950 4550 0
								 900 4545 0
								 850 4530 0
								 750 4520 0
								 650 4510 1>;
				strategy_temp_range_t2 =	<1100 4550 0
								 1050 4545 0
								 950  4530 0
								 850  4520 0
								 700  4510 1>;
				strategy_temp_range_t3 =	<1200 4550 0
								 1150 4545 0
								 1050 4530 0
								 950  4520 0
								 800  4510 1>;
				strategy_temp_range_t4 =	<2700 4550 0
								 2500 4550 0
								 2000 4545 0
								 1500 4530 0
								 1000 4515 1>;
				strategy_temp_range_t5 =	<2800 4534 0
								 2600 4531 0
								 2100 4520 0
								 1600 4505 0
								 1000 4475 1>;
			};
		};

		svooc_charge_strategy {
			strategy_soc_0_to_50 { /* 0 ~ 20 */
				strategy_temp_little_cold =	<4130 10 1 0 0>;
				strategy_temp_cool =		<3980 16 0 0 0
								3980 15 0 0 0
								4120 11 0 0 0
								4130 10 1 0 0>;
				strategy_temp_little_cool =	<4080 26 0 0 0
								4080 25 0 0 0
								4080 20 0 0 0
								4230 16 0 0 0
								4230 15 0 0 0
								4420 11 0 0 0
								4430 10 1 0 0>;
				strategy_temp_little_cool_high =	<4080 33 0 0 0
								4080 30 0 0 0
								4230 26 0 0 0
								4230 25 0 0 0
								4230 20 0 0 0
								4510 16 0 0 0
								4510 15 0 0 0
								4550 10 1 0 0>;
				strategy_temp_normal_low =	<4100 73 0 60 0
								4100 70 0 30 0
								4100 60 0 120 0
								4110 52 0 320 0
								4110 50 0 320 0
								4110 45 0 0 0
								4380 43 0 0 0
								4510 42 0 0 0
								4510 40 0 0 0
								4540 35 0 0 0
								4540 30 0 0 0
								4540 25 0 0 0
								4540 20 0 0 0
								4550 15 0 0 0
								4525 10 1 0 0>;
				strategy_temp_normal_high =	<4100 73 0 60 0
								4100 70 0 30 0
								4100 60 0 120 0
								4110 52 0 320 0
								4110 50 0 320 0
								4110 45 0 0 0
								4380 43 0 0 0
								4510 42 0 0 0
								4510 40 0 0 0
								4540 35 0 0 0
								4540 30 0 0 0
								4540 25 0 0 0
								4540 20 0 0 0
								4550 16 0 0 0
								4525 10 1 0 0>;
				strategy_temp_warm =		<4120 20 0 0 0
								4120 15 0 0 0
								4130 10 1 0 0>;
			};

			strategy_soc_0_to_50_mid { /* 21 ~ 35 */
				strategy_temp_little_cold =	<4130 10 1 0 0>;
				strategy_temp_cool =		<3980 16 0 0 0
								3980 15 0 0 0
								4120 11 0 0 0
								4130 10 1 0 0>;
				strategy_temp_little_cool =	<4080 26 0 0 0
								4080 25 0 0 0
								4080 20 0 0 0
								4230 16 0 0 0
								4230 15 0 0 0
								4420 11 0 0 0
								4430 10 1 0 0>;
				strategy_temp_little_cool_high =	<4080 33 0 0 0
								4080 30 0 0 0
								4230 26 0 0 0
								4230 25 0 0 0
								4230 20 0 0 0
								4510 16 0 0 0
								4510 15 0 0 0
								4550 10 1 0 0>;
				strategy_temp_normal_low =	<4100 73 0 60 0
								4100 70 0 30 0
								4100 60 0 120 0
								4110 52 0 320 0
								4110 50 0 320 0
								4110 45 0 0 0
								4380 43 0 0 0
								4510 42 0 0 0
								4510 40 0 0 0
								4540 35 0 0 0
								4540 30 0 0 0
								4540 25 0 0 0
								4540 20 0 0 0
								4550 15 0 0 0
								4525 10 1 0 0>;
				strategy_temp_normal_high =	<4100 73 0 60 0
								4100 70 0 30 0
								4100 60 0 120 0
								4110 52 0 320 0
								4110 50 0 320 0
								4110 45 0 0 0
								4380 43 0 0 0
								4510 42 0 0 0
								4510 40 0 0 0
								4540 35 0 0 0
								4540 30 0 0 0
								4540 25 0 0 0
								4540 20 0 0 0
								4550 16 0 0 0
								4525 10 1 0 0>;
				strategy_temp_warm =		<4120 20 0 0 0
								4120 15 0 0 0
								4130 10 1 0 0>;
			};

			strategy_soc_0_to_50_high { /* 36 ~ 55 */
				strategy_temp_little_cold =	<4130 10 1 0 0>;
				strategy_temp_cool =		<3980 16 0 0 0
								3980 15 0 0 0
								4120 11 0 0 0
								4130 10 1 0 0>;
				strategy_temp_little_cool =	<4080 26 0 0 0
								4080 25 0 0 0
								4080 20 0 0 0
								4230 16 0 0 0
								4230 15 0 0 0
								4420 11 0 0 0
								4430 10 1 0 0>;
				strategy_temp_little_cool_high =	<4080 33 0 0 0
								4080 30 0 0 0
								4230 26 0 0 0
								4230 25 0 0 0
								4230 20 0 0 0
								4510 16 0 0 0
								4510 15 0 0 0
								4550 10 1 0 0>;
				strategy_temp_normal_low =	<4100 73 0 60 0
								4100 70 0 30 0
								4100 60 0 120 0
								4110 52 0 320 0
								4110 50 0 320 0
								4110 45 0 0 0
								4380 43 0 0 0
								4510 42 0 0 0
								4510 40 0 0 0
								4540 35 0 0 0
								4540 30 0 0 0
								4540 25 0 0 0
								4540 20 0 0 0
								4550 15 0 0 0
								4525 10 1 0 0>;
				strategy_temp_normal_high =	<4100 73 0 60 0
								4100 70 0 30 0
								4100 60 0 120 0
								4110 52 0 320 0
								4110 50 0 320 0
								4110 45 0 0 0
								4380 43 0 0 0
								4510 42 0 0 0
								4510 40 0 0 0
								4540 35 0 0 0
								4540 30 0 0 0
								4540 25 0 0 0
								4540 20 0 0 0
								4550 16 0 0 0
								4525 10 1 0 0>;
				strategy_temp_warm =		<4120 20 0 0 0
								4120 15 0 0 0
								4130 10 1 0 0>;
			};

			strategy_soc_50_to_75 { /* 56 ~ 75 */
				strategy_temp_little_cold =	<4130 10 1 0 0>;
				strategy_temp_cool =		<3980 15 0 0 0
								4120 11 0 0 0
								4130 10 1 0 0>;
				strategy_temp_little_cool =	<4080 20 0 0 0
								4230 16 0 0 0
								4230 15 0 0 0
								4420 11 0 0 0
								4430 10 1 0 0>;
				strategy_temp_little_cool_high =	<4230 20 0 0 0
								4510 16 0 0 0
								4510 15 0 0 0
								4550 10 1 0 0>;
				strategy_temp_normal_low =	<4540 25 0 0 0
								4540 20 0 0 0
								4550 15 0 0 0
								4525 10 1 0 0>;
				strategy_temp_normal_high =	<4540 30 0 0 0
								4540 25 0 0 0
								4540 20 0 0 0
								4550 16 0 0 0
								4525 10 1 0 0>;
				strategy_temp_warm =		<4130 10 1 0 0>;
			};

			strategy_soc_75_to_85 { /* 76 ~ 85 */
				strategy_temp_little_cold =	<4130 10 1 0 0>;
				strategy_temp_cool =		<4130 10 1 0 0>;
				strategy_temp_little_cool =	<4230 15 0 0 0
								4420 11 0 0 0
								4430 10 1 0 0>;
				strategy_temp_little_cool_high =	<4510 15 0 0 0
								4550 10 1 0 0>;
				strategy_temp_normal_low =	<4540 20 0 0 0
								4550 15 0 0 0
								4525 10 1 0 0>;
				strategy_temp_normal_high =	<4540 25 0 0 0
								4540 20 0 0 0
								4550 16 0 0 0
								4525 10 1 0 0>;
				strategy_temp_warm =		<4130 10 1 0 0>;
			};

			strategy_soc_85_to_90 { /* 86 ~ 95 */
				strategy_temp_little_cold =	<4130 10 1 0 0>;
				strategy_temp_cool =		<4130 10 1 0 0>;
				strategy_temp_little_cool =	<4430 10 1 0 0>;
				strategy_temp_little_cool_high = <4550 10 1 0 0>;
				strategy_temp_normal_low =	<4550 15 0 0 0
								4525 10 1 0 0>;
				strategy_temp_normal_high =	<4550 16 0 0 0
								4525 10 1 0 0>;
				strategy_temp_warm =		<4130 10 1 0 0>;
			};
		};

		vooc_charge_strategy {
			strategy_soc_0_to_50 {
				strategy_temp_little_cold =	<4130 20 1 0 0>;
				strategy_temp_cool =		<3980 32 0 0 0
								3980 30 0 0 0
								4120 22 0 0 0
								4130 20 1 0 0>;
				strategy_temp_little_cool =	<4080 52 0 0 0
								4080 50 0 0 0
								4080 40 0 0 0
								4230 32 0 0 0
								4230 30 0 0 0
								4420 22 0 0 0
								4430 20 1 0 0>;
				strategy_temp_little_cool_high =	<4080 60 0 0 0
								4230 52 0 0 0
								4230 50 0 0 0
								4230 40 0 0 0
								4510 32 0 0 0
								4510 30 0 0 0
								4550 20 1 0 0>;
				strategy_temp_normal_low =	<4540 60 0 0 0
								4540 50 0 0 0
								4540 40 0 0 0
								4550 30 0 0 0
								4525 20 1 0 0>;
				strategy_temp_normal_high =	<4540 60 0 0 0
								4540 50 0 0 0
								4540 40 0 0 0
								4550 32 0 0 0
								4525 20 1 0 0>;
				strategy_temp_warm =		<4120 40 0 0 0
								4120 30 0 0 0
								4130 20 1 0 0>;
			};

			strategy_soc_0_to_50_mid {
				strategy_temp_little_cold =	<4130 20 1 0 0>;
				strategy_temp_cool =		<3980 32 0 0 0
								3980 30 0 0 0
								4120 22 0 0 0
								4130 20 1 0 0>;
				strategy_temp_little_cool =	<4080 52 0 0 0
								4080 50 0 0 0
								4080 40 0 0 0
								4230 32 0 0 0
								4230 30 0 0 0
								4420 22 0 0 0
								4430 20 1 0 0>;
				strategy_temp_little_cool_high =	<4080 60 0 0 0
								4230 52 0 0 0
								4230 50 0 0 0
								4230 40 0 0 0
								4510 32 0 0 0
								4510 30 0 0 0
								4550 20 1 0 0>;
				strategy_temp_normal_low =	<4540 60 0 0 0
								4540 50 0 0 0
								4540 40 0 0 0
								4550 30 0 0 0
								4525 20 1 0 0>;
				strategy_temp_normal_high =	<4540 60 0 0 0
								4540 50 0 0 0
								4540 40 0 0 0
								4550 32 0 0 0
								4525 20 1 0 0>;
				strategy_temp_warm =		<4120 40 0 0 0
								4120 30 0 0 0
								4130 20 1 0 0>;
			};

			strategy_soc_0_to_50_high {
				strategy_temp_little_cold =	<4130 20 1 0 0>;
				strategy_temp_cool =		<3980 32 0 0 0
								3980 30 0 0 0
								4120 22 0 0 0
								4130 20 1 0 0>;
				strategy_temp_little_cool =	<4080 52 0 0 0
								4080 50 0 0 0
								4080 40 0 0 0
								4230 32 0 0 0
								4230 30 0 0 0
								4420 22 0 0 0
								4430 20 1 0 0>;
				strategy_temp_little_cool_high =	<4080 60 0 0 0
								4230 52 0 0 0
								4230 50 0 0 0
								4230 40 0 0 0
								4510 32 0 0 0
								4510 30 0 0 0
								4550 20 1 0 0>;
				strategy_temp_normal_low =	<4540 60 0 0 0
								4540 50 0 0 0
								4540 40 0 0 0
								4550 30 0 0 0
								4525 20 1 0 0>;
				strategy_temp_normal_high =	<4540 60 0 0 0
								4540 50 0 0 0
								4540 40 0 0 0
								4550 32 0 0 0
								4525 20 1 0 0>;
				strategy_temp_warm =		<4120 40 0 0 0
								4120 30 0 0 0
								4130 20 1 0 0>;
			};

			strategy_soc_50_to_75 {
				strategy_temp_little_cold =	<4130 20 1 0 0>;
				strategy_temp_cool =		<3980 30 0 0 0
								4120 22 0 0 0
								4130 20 1 0 0>;
				strategy_temp_little_cool =	<4080 40 0 0 0
								4230 32 0 0 0
								4230 30 0 0 0
								4420 22 0 0 0
								4430 20 1 0 0>;
				strategy_temp_little_cool_high =	<4230 40 0 0 0
								4510 32 0 0 0
								4510 30 0 0 0
								4550 20 1 0 0>;
				strategy_temp_normal_low =	<4540 50 0 0 0
								4540 40 0 0 0
								4550 30 0 0 0
								4525 20 1 0 0>;
				strategy_temp_normal_high =	<4540 60 0 0 0
								4540 50 0 0 0
								4540 40 0 0 0
								4550 32 0 0 0
								4525 20 1 0 0>;
				strategy_temp_warm =		<4130 20 1 0 0>;
			};

			strategy_soc_75_to_85 {
				strategy_temp_little_cold =	<4130 20 1 0 0>;
				strategy_temp_cool =		<4130 20 1 0 0>;
				strategy_temp_little_cool =	<4230 30 0 0 0
								4420 22 0 0 0
								4430 20 1 0 0>;
				strategy_temp_little_cool_high =	<4510 30 0 0 0
								4550 20 1 0 0>;
				strategy_temp_normal_low =	<4540 40 0 0 0
								4550 30 0 0 0
								4525 20 1 0 0>;
				strategy_temp_normal_high =	<4540 50 0 0 0
								4540 40 0 0 0
								4550 32 0 0 0
								4525 20 1 0 0>;
				strategy_temp_warm =		<4130 20 1 0 0>;
			};

			strategy_soc_85_to_90 {
				strategy_temp_little_cold =	<4130 20 1 0 0>;
				strategy_temp_cool =		<4130 20 1 0 0>;
				strategy_temp_little_cool =	<4430 20 1 0 0>;
				strategy_temp_little_cool_high = <4550 20 1 0 0>;
				strategy_temp_normal_low =	<4550 30 0 0 0
								4525 20 1 0 0>;
				strategy_temp_normal_high =	<4550 32 0 0 0
								4525 20 1 0 0>;
				strategy_temp_warm =		<4130 20 1 0 0>;
			};
		};

		oplus_sc8547_cp: oplus,sc8547_cp {
			oplus,ic_type = <OPLUS_CHG_IC_CP>;
			oplus,ic_index = <0>;
			oplus,ic_func_group = <&sc8547_cp_groups>;
		};
	};
};

&i2c13 {
	status = "okay";
	clock-frequency = <400000>;
	oplus_sc8547_slave: sc8547-charger-slave@6A{
		status = "okay";
		compatible = "oplus,sc8547d";
		reg = <0x6A>;

		oplus,use_slave_cp;
		oplus_spec,irq_gpio = <&pio 61 0x00>;
		interrupt-parent = <&pio>;

		pinctrl-names = "default", "charging_inter_active", "charging_inter_sleep";
		pinctrl-0 = <&i2c13_mode_default>;
		pinctrl-1 = <&slave_charging_inter_active>;
		pinctrl-2 = <&slave_charging_inter_sleep>;

		ocp_reg = <0xe>;
		ovp_reg = <0x36>;/* vbat ovp 4.85v */
		vbus_ovp_reg = /bits/ 8 <0x5A>;  /* vbus ovp: 10.5v */
		oplus_sc8547_slave_cp: oplus,sc8547_slave_cp {
			oplus,ic_type = <OPLUS_CHG_IC_CP>;
			oplus,ic_index = <1>;
			oplus,ic_func_group = <&sc8547_cp_groups>;
		};
	};

	byb_hl7603: byb-hl7603@75 {
		status = "okay";
		compatible = "oplus,byb-hl7603";
		reg = <0x75>;
		oplus,ic_type = <OPLUS_CHG_IC_BOOST>;
		oplus,ic_index = <0>;
		oplus,vout-mv = <3950>;
		oplus,ilim-ma = <6000>;
	};

};

&i2c12 {
	status = "okay";
	clock-frequency = <400000>;
	pinctrl-names = "i2c-state", "output-low-state";
	pinctrl-0 = <&i2c12_i2c_state>;
	pinctrl-1 = <&i2c12_output_low_state>;
	sc83107-charger@69s {
		compatible = "oplus,sc83107";
		reg = <0x69>;
		status = "okay";

		oplus,sc83107,irq-gpio = <&pio 42 0x00>;
		interrupt-parent = <&pio>;
		interrupts = <42 0>;

		pinctrl-names = "boost_inter_active", "boost_inter_sleep";
		pinctrl-0 = <&boost_inter_active>;
		pinctrl-1 = <&boost_inter_sleep>;

		oplus,sc83107,operation-mode = <0>;/*0: Auto Hybrid Boost Bypass 1: Force Bypass*/
		oplus,sc83107,freq = <0>; /*0: 1MHZ 1: 700KHZ*/
		oplus,sc83107,otg-mode = <0>; /*0:disable 1:enable*/
		oplus,sc83107,wdt-timeout = <0>; /*0:disable, 1:0.5s, 2:1s, 3:2s,
							4:20s, 5:40s, 6:80s, 7:160s*/
		oplus,sc83107,vout-ovp-dis = <0>; /*0:enable 1:disable*/
		oplus,sc83107,current-limit-dis = <0>; /*0:enable 1:disable*/
		/* I2C bus reset feature control: 0=disabled (default), 1=enabled */
		oplus,sc83107,i2c-bus-reset-enable;

		oplus_sc83107_boost: oplus,sc83107_boost {
			oplus,ic_type = <OPLUS_CHG_IC_BOOST>;
			oplus,ic_index = <0>;
			oplus,ic_func_group = <&sc83107_boost_groups>;
		};
	};
};

&pio {
	i2c13_mode_default: i2c13_mode_default {
		pins_cmd_dat {
			pinmux = <PINMUX_GPIO163__FUNC_SCL13>,
				<PINMUX_GPIO164__FUNC_SDA13>;
			bias-pull-up = <MTK_PULL_SET_RSEL_111>;
		};
	};

	slave_charging_inter_active: slave_charging_inter_active {
		pins_cmd_dat {
			pinmux = <PINMUX_GPIO61__FUNC_GPIO61>;
			input-enable;
			bias-pull-up;
		};
	};

	slave_charging_inter_sleep: slave_charging_inter_sleep {
		pins_cmd_dat {
			pinmux = <PINMUX_GPIO61__FUNC_GPIO61>;
			input-enable;
			bias-pull-up;
		};
	};

	boost_inter_active: boost_inter_active {
		pins_cmd_dat {
			pinmux = <PINMUX_GPIO42__FUNC_GPIO42>;
			input-enable;
			bias-pull-up;
		};
	};

	boost_inter_sleep: boost_inter_sleep {
		pins_cmd_dat {
			pinmux = <PINMUX_GPIO42__FUNC_GPIO42>;
			input-enable;
			bias-pull-up;
		};
	};

	i2c12_i2c_state: i2c12_sda_i2c_state {
		pins_cmd_dat {
			pinmux = <PINMUX_GPIO161__FUNC_SCL12>,
			<PINMUX_GPIO162__FUNC_SDA12>;
			bias-pull-up;
		};
	};
	i2c12_output_low_state: i2c12_sda_output_low_state {
		pins_cmd_dat {
			pinmux = <PINMUX_GPIO161__FUNC_GPIO161>,
			<PINMUX_GPIO162__FUNC_GPIO162>;
			output-low;
		};
	};
};

//for ufcs config
&soc {
	oplus_ufcs_impedance_check: oplus,ufcs_impedance_check {
		compatible = "oplus,impedance_check";

		oplus,impedance_unit {
			oplus_ufcs_impedance_unit: oplus,ufcs_impedance_unit {
				uint_name = "ufcs";
				default_curr_ma = <7300>;
				impedance_node = <&ufcs_input_impedance>;
			};
		};
	};
};

&soc {
	oplus_cpa: oplus,cpa {
		compatible = "oplus,cpa";
		oplus,protocol_list = <CHG_PROTOCOL_UFCS 80
				       CHG_PROTOCOL_PD 18
				       CHG_PROTOCOL_VOOC 80
				       CHG_PROTOCOL_QC 18>;
		oplus,default_protocol_list = <CHG_PROTOCOL_UFCS
					       CHG_PROTOCOL_PD
					       CHG_PROTOCOL_VOOC>;
	};

	oplus_virtual_ufcs: oplus,virtual_ufcs {
		compatible = "oplus,virtual_ufcs";

		oplus,ic_type = <OPLUS_CHG_IC_VIRTUAL_UFCS>;
		oplus,ic_index = <0>;
	};

	oplus_ufcs_charge: oplus,ufcs_charge {
		compatible = "oplus,ufcs_charge";
		oplus,ufcs_ic = <&oplus_virtual_ufcs>;
		oplus,cp_ic = <&oplus_virtual_cp>;
		oplus,dpdm_switch_ic = <&oplus_virtual_dpdm_switch>;

		oplus,impedance_unit = <&oplus_ufcs_impedance_unit>;

		oplus,target_vbus_mv = <11000>;
		oplus,curr_max_ma = <7300>;
		oplus,curr_max_ma_percent = <3000 /* 75% ibus */
						2000 /* 85% ibus */>;

		oplus,curr_table_type = <UFCS_CURR_CP_TABLE>;
		oplus,high_imp_compensation_setting_mv = <250>;
		oplus,upper_compensation_mv = <200>;
		oplus,lift_vbus_use_cpvout;
		oplus,subboard_ntc_abnormal_current = <4000>;

		oplus,ufcs_warm_allow_vol = <4000>;
		oplus,ufcs_warm_allow_soc = <55>;
		oplus,ufcs_strategy_normal_current = <7300>;
		oplus,ufcs_over_high_or_low_current = <7300>;
		oplus,ufcs_timeout_third = <18681>;
		oplus,ufcs_timeout_oplus = <18681>;
		oplus,ufcs_ibat_over_third = <9400>;
		oplus,ufcs_ibat_over_oplus = <16000>;
		oplus,ufcs_ibus_over_oplus = <8000>;
		oplus,ufcs_full_cool_sw_vbat = <4130>;
		oplus,ufcs_full_normal_sw_vbat = <4550>;
		oplus,ufcs_full_normal_hw_vbat = <4560>;
		oplus,ufcs_full_ffc_vbat = <4550>;
		oplus,ufcs_full_warm_vbat = <4130>;
		oplus,ufcs_full_cool_sw_vbat_third = <4130>;
		oplus,ufcs_full_normal_sw_vbat_third= <4500>;
		oplus,ufcs_full_normal_hw_vbat_third = <4540>;
		oplus,ufcs_current_change_timeout = <100>;
		oplus,ufcs_strategy_batt_high_temp = <405 420 430 395 410 425>;
		oplus,ufcs_strategy_high_current = <5000 4000 3000 3000 4000 5000>;
		oplus,ufcs_little_cool_high_temp = <210>;
		oplus,curve_strategy_name = "pps_ufcs_curve_v2";
		oplus,ufcs_full_recheck_temp = <210>;
		oplus_spec,ufcs_high_soc = <90>;
		oplus_spec,ufcs_low_soc = <0>;
		oplus_spec,ufcs_high_temp = <500>;
		oplus_spec,ufcs_low_temp = <50>;
		oplus_spec,ufcs_high_soc_third = <85>;
		oplus,ufcs_charge_strategy_temp = <50 50 120 160 350 440 510>;

		oplus,ufcs_vfa_strategy = <&ratio2t1_vfa_strategy>;

		oplus,plc_strategy-data = <&oplus_ufcs_step_strategy &cp_2t1_simple_strategy>;
		oplus,plc_strategy-names = "default", "third";

		oplus,temperature_strategy_name = "cgcl";
		oplus,temperature_strategy_data = <OPLUS_STRATEGY_USE_SHELL_TEMP
						0   385 7300 1 0
						375 405 5000 2 0
						395 420 4000 3 1
						410 430 3500 4 2
						420 440 2000 4 3>;
		ufcs_oplus_lcf_strategy {
			oplus,temp_type = <OPLUS_STRATEGY_USE_SHELL_TEMP>;
			oplus,temp_range = <0 50 120 160 210 380 440>;

			strategy_temp_range_curves {
				strategy_temp_range_t0 =	<350 4500 0
								 325 4490 0
								 300 4480 0
								 275 4470 0
								 250 4460 1>;
				strategy_temp_range_t1 =	<950 4550 0
								 900 4545 0
								 850 4530 0
								 750 4520 0
								 650 4510 1>;
				strategy_temp_range_t2 =	<1100 4550 0
								 1050 4545 0
								 950  4530 0
								 850  4520 0
								 700  4510 1>;
				strategy_temp_range_t3 =	<1200 4550 0
								 1150 4545 0
								 1050 4530 0
								 950  4520 0
								 800  4510 1>;
				strategy_temp_range_t4 =	<2700 4550 0
								 2500 4550 0
								 2000 4545 0
								 1500 4530 0
								 1000 4515 1>;
				strategy_temp_range_t5 =	<2800 4534 0
								 2600 4531 0
								 2100 4520 0
								 1600 4505 0
								 1000 4475 1>;
			};
		};

		ufcs_third_lcf_strategy {
			oplus,temp_type = <OPLUS_STRATEGY_USE_SHELL_TEMP>;
			oplus,temp_range = <0 50 120 160 210 380 440>;

			strategy_temp_range_curves {
				strategy_temp_range_t0 =	<350 4500 0
								 325 4490 0
								 300 4480 0
								 275 4470 0
								 250 4460 1>;
				strategy_temp_range_t1 =	<950 4550 0
								 900 4545 0
								 850 4530 0
								 750 4520 0
								 650 4510 1>;
				strategy_temp_range_t2 =	<1100 4550 0
								 1050 4545 0
								 950  4530 0
								 850  4520 0
								 700  4510 1>;
				strategy_temp_range_t3 =	<1200 4550 0
								 1150 4545 0
								 1050 4530 0
								 950  4520 0
								 800  4510 1>;
				strategy_temp_range_t4 =	<2700 4550 0
								 2500 4550 0
								 2000 4545 0
								 1500 4530 0
								 1000 4515 1>;
				strategy_temp_range_t5 =	<2800 4534 0
								 2600 4531 0
								 2100 4520 0
								 1600 4505 0
								 1000 4475 1>;
			};
		};

		ufcs_charge_third_strategy {
			oplus,temp_type = <OPLUS_STRATEGY_USE_SHELL_TEMP>;
			oplus,soc_range = <0 20 35 55 75 85 90>;
			oplus,temp_range = <0 50 120 160 210 350 440 510>;

			strategy_soc_range_min {
				strategy_temp_little_cold =	<11000 4130 1000 1 0>;
				strategy_temp_cool =		<11000 3980 1650 0 0
								11000 3980 1500 0 0
								11000 4120 1150 0 0
								11000 4130 1000 1 0>;
				strategy_temp_little_cool =	<11000 4080 2650 0 0
								11000 4080 2500 0 0
								11000 4080 2000 0 0
								11000 4230 1650 0 0
								11000 4230 1500 0 0
								11000 4420 1150 0 0
								11000 4430 1000 1 0>;
				strategy_temp_little_cool_high =	<11000 4080 3350 0 0
								11000 4080 3000 0 0
								11000 4230 2650 0 0
								11000 4230 2500 0 0
								11000 4230 2000 0 0
								11000 4490 1650 0 0
								11000 4490 1500 0 0
								11000 4490 1050 0 0
								11000 4500 1000 1 0>;
				strategy_temp_normal_low =	<11000 4490 4000 0 0
								11000 4490 3500 0 0
								11000 4490 3000 0 0
								11000 4490 2500 0 0
								11000 4490 2000 0 0
								11000 4490 1500 0 0
								11000 4500 1000 1 0>;
				strategy_temp_normal_high =	<11000 4475 4000 0 0
								11000 4475 3500 0 0
								11000 4475 3000 0 0
								11000 4475 2500 0 0
								11000 4475 2000 0 0
								11000 4475 1500 0 0
								11000 4485 1000 1 0>;
				strategy_temp_warm =		<11000 4120 1950 0 0
								11000 4120 1500 0 0
								11000 4130 1000 1 0>;
			};
			strategy_soc_range_low {
				strategy_temp_little_cold =	<11000 4130 1000 1 0>;
				strategy_temp_cool =		<11000 3980 1650 0 0
								11000 3980 1500 0 0
								11000 4120 1150 0 0
								11000 4130 1000 1 0>;
				strategy_temp_little_cool =	<11000 4080 2650 0 0
								11000 4080 2500 0 0
								11000 4080 2000 0 0
								11000 4230 1650 0 0
								11000 4230 1500 0 0
								11000 4420 1150 0 0
								11000 4430 1000 1 0>;
				strategy_temp_little_cool_high =	<11000 4080 3350 0 0
								11000 4080 3000 0 0
								11000 4230 2650 0 0
								11000 4230 2500 0 0
								11000 4230 2000 0 0
								11000 4490 1650 0 0
								11000 4490 1500 0 0
								11000 4490 1050 0 0
								11000 4500 1000 1 0>;
				strategy_temp_normal_low =	<11000 4490 4000 0 0
								11000 4490 3500 0 0
								11000 4490 3000 0 0
								11000 4490 2500 0 0
								11000 4490 2000 0 0
								11000 4490 1500 0 0
								11000 4500 1000 1 0>;
				strategy_temp_normal_high =	<11000 4475 4000 0 0
								11000 4475 3500 0 0
								11000 4475 3000 0 0
								11000 4475 2500 0 0
								11000 4475 2000 0 0
								11000 4475 1500 0 0
								11000 4485 1000 1 0>;
				strategy_temp_warm =		<11000 4120 1950 0 0
								11000 4120 1500 0 0
								11000 4130 1000 1 0>;
			};
			strategy_soc_range_mid_low {
				strategy_temp_little_cold =	<11000 4130 1000 1 0>;
				strategy_temp_cool =		<11000 3980 1650 0 0
								11000 3980 1500 0 0
								11000 4120 1150 0 0
								11000 4130 1000 1 0>;
				strategy_temp_little_cool =	<11000 4080 2650 0 0
								11000 4080 2500 0 0
								11000 4080 2000 0 0
								11000 4230 1650 0 0
								11000 4230 1500 0 0
								11000 4420 1150 0 0
								11000 4430 1000 1 0>;
				strategy_temp_little_cool_high =	<11000 4080 3000 0 0
								11000 4230 2650 0 0
								11000 4230 2500 0 0
								11000 4230 2000 0 0
								11000 4490 1650 0 0
								11000 4490 1500 0 0
								11000 4490 1050 0 0
								11000 4500 1000 1 0>;
				strategy_temp_normal_low =	<11000 4490 4000 0 0
								11000 4490 3500 0 0
								11000 4490 3000 0 0
								11000 4490 2500 0 0
								11000 4490 2000 0 0
								11000 4490 1500 0 0
								11000 4500 1000 1 0>;
				strategy_temp_normal_high =	<11000 4475 4000 0 0
								11000 4475 3500 0 0
								11000 4475 3000 0 0
								11000 4475 2500 0 0
								11000 4475 2000 0 0
								11000 4475 1500 0 0
								11000 4485 1000 1 0>;
				strategy_temp_warm =		<11000 4120 1950 0 0
								11000 4120 1500 0 0
								11000 4130 1000 1 0>;
			};
			strategy_soc_range_mid {
				strategy_temp_little_cold =	<11000 4130 1000 1 0>;
				strategy_temp_cool =		<11000 3980 1500 0 0
								11000 4120 1150 0 0
								11000 4130 1000 1 0>;
				strategy_temp_little_cool =	<11000 4080 2000 0 0
								11000 4230 1650 0 0
								11000 4230 1500 0 0
								11000 4420 1150 0 0
								11000 4430 1000 1 0>;
				strategy_temp_little_cool_high =	<11000 4230 2000 0 0
								11000 4490 1650 0 0
								11000 4490 1500 0 0
								11000 4490 1050 0 0
								11000 4500 1000 1 0>;
				strategy_temp_normal_low =	<11000 4490 2000 0 0
								11000 4490 1500 0 0
								11000 4500 1000 1 0>;
				strategy_temp_normal_high =	<11000 4475 2500 0 0
								11000 4475 2000 0 0
								11000 4475 1500 0 0
								11000 4485 1000 1 0>;
				strategy_temp_warm =		<11000 4130 1000 1 0>;
			};
			strategy_soc_range_mid_high {
				strategy_temp_little_cold =	<11000 4130 1000 1 0>;
				strategy_temp_cool =		<11000 4130 1000 1 0>;
				strategy_temp_little_cool =	<11000 4230 1500 0 0
								11000 4420 1150 0 0
								11000 4430 1000 1 0>;
				strategy_temp_little_cool_high =	<11000 4490 1500 0 0
								11000 4490 1050 0 0
								11000 4500 1000 1 0>;
				strategy_temp_normal_low =	<11000 4490 2000 0 0
								11000 4490 1500 0 0
								11000 4500 1000 1 0>;
				strategy_temp_normal_high =	<11000 4475 2000 0 0
								11000 4475 1500 0 0
								11000 4485 1000 1 0>;
				strategy_temp_warm =		<11000 4130 1000 1 0>;
			};
			strategy_soc_range_high {
				strategy_temp_little_cold =	<11000 4130 1000 1 0>;
				strategy_temp_cool =		<11000 4130 1000 1 0>;
				strategy_temp_little_cool =	<11000 4430 1000 1 0>;
				strategy_temp_little_cool_high =	<11000 4500 1000 1 0>;
				strategy_temp_normal_low =	<11000 4500 1000 1 0>;
				strategy_temp_normal_high =	<11000 4475 1500 0 0
								11000 4485 1000 1 0>;
				strategy_temp_warm =		<11000 4130 1000 1 0>;
			};
		};

		ufcs_charge_oplus_strategy {
			oplus,temp_type = <OPLUS_STRATEGY_USE_SHELL_TEMP>;
			oplus,soc_range = <0 20 35 55 75 85 90>;
			oplus,temp_range = <0 50 120 160 210 350 440 510>;

			strategy_soc_range_min {
				strategy_temp_little_cold =	<11000 4130 1000 1 0>;
				strategy_temp_cool =		<11000 3980 1650 0 0
								11000 3980 1500 0 0
								11000 4120 1150 0 0
								11000 4130 1000 1 0>;
				strategy_temp_little_cool =	<11000 4080 2650 0 0
								11000 4080 2500 0 0
								11000 4080 2000 0 0
								11000 4230 1650 0 0
								11000 4230 1500 0 0
								11000 4420 1150 0 0
								11000 4430 1000 1 0>;
				strategy_temp_little_cool_high =	<11000 4080 3350 0 0
								11000 4080 3000 0 0
								11000 4230 2650 0 0
								11000 4230 2500 0 0
								11000 4230 2000 0 0
								11000 4510 1650 0 0
								11000 4510 1500 0 0
								11000 4540 1050 0 0
								11000 4550 1000 1 0>;
				strategy_temp_normal_low =	<11000 4100 7300 0 30
								11000 4100 7000 0 15
								11000 4100 6000 0 60
								11000 4110 5250 0 160
								11000 4110 5000 0 160
								11000 4110 4500 0 0
								11000 4380 4350 0 0
								11000 4510 4200 0 0
								11000 4510 4000 0 0
								11000 4540 3500 0 0
								11000 4540 3000 0 0
								11000 4540 2500 0 0
								11000 4540 2000 0 0
								11000 4550 1500 0 0
								11000 4525 1000 1 0>;
				strategy_temp_normal_high =	<11000 4100 7300 0 30
								11000 4100 7000 0 15
								11000 4100 6000 0 60
								11000 4110 5250 0 160
								11000 4110 5000 0 160
								11000 4110 4500 0 0
								11000 4380 4350 0 0
								11000 4510 4200 0 0
								11000 4510 4000 0 0
								11000 4540 3500 0 0
								11000 4540 3000 0 0
								11000 4540 2500 0 0
								11000 4540 2000 0 0
								11000 4550 1550 0 0
								11000 4525 1000 1 0>;
				strategy_temp_warm =		<11000 4120 1950 0 0
								11000 4120 1500 0 0
								11000 4130 1000 1 0>;
			};
			strategy_soc_range_low {
				strategy_temp_little_cold =	<11000 4130 1000 1 0>;
				strategy_temp_cool =		<11000 3980 1650 0 0
								11000 3980 1500 0 0
								11000 4120 1150 0 0
								11000 4130 1000 1 0>;
				strategy_temp_little_cool =	<11000 4080 2650 0 0
								11000 4080 2500 0 0
								11000 4080 2000 0 0
								11000 4230 1650 0 0
								11000 4230 1500 0 0
								11000 4420 1150 0 0
								11000 4430 1000 1 0>;
				strategy_temp_little_cool_high =	<11000 4080 3350 0 0
								11000 4080 3000 0 0
								11000 4230 2650 0 0
								11000 4230 2500 0 0
								11000 4230 2000 0 0
								11000 4510 1650 0 0
								11000 4510 1500 0 0
								11000 4540 1050 0 0
								11000 4550 1000 1 0>;
				strategy_temp_normal_low =	<11000 4100 7300 0 30
								11000 4100 7000 0 15
								11000 4100 6000 0 60
								11000 4110 5250 0 160
								11000 4110 5000 0 160
								11000 4110 4500 0 0
								11000 4380 4350 0 0
								11000 4510 4200 0 0
								11000 4510 4000 0 0
								11000 4540 3500 0 0
								11000 4540 3000 0 0
								11000 4540 2500 0 0
								11000 4540 2000 0 0
								11000 4550 1500 0 0
								11000 4525 1000 1 0>;
				strategy_temp_normal_high =	<11000 4100 7300 0 30
								11000 4100 7000 0 15
								11000 4100 6000 0 60
								11000 4110 5250 0 160
								11000 4110 5000 0 160
								11000 4110 4500 0 0
								11000 4380 4350 0 0
								11000 4510 4200 0 0
								11000 4510 4000 0 0
								11000 4540 3500 0 0
								11000 4540 3000 0 0
								11000 4540 2500 0 0
								11000 4540 2000 0 0
								11000 4550 1550 0 0
								11000 4525 1000 1 0>;
				strategy_temp_warm =		<11000 4120 1950 0 0
								11000 4120 1500 0 0
								11000 4130 1000 1 0>;
			};
			strategy_soc_range_mid_low {
				strategy_temp_little_cold =	<11000 4130 1000 1 0>;
				strategy_temp_cool =		<11000 3980 1650 0 0
								11000 3980 1500 0 0
								11000 4120 1150 0 0
								11000 4130 1000 1 0>;
				strategy_temp_little_cool =	<11000 4080 2650 0 0
								11000 4080 2500 0 0
								11000 4080 2000 0 0
								11000 4230 1650 0 0
								11000 4230 1500 0 0
								11000 4420 1150 0 0
								11000 4430 1000 1 0>;
				strategy_temp_little_cool_high =	<11000 4080 3350 0 0
								11000 4080 3000 0 0
								11000 4230 2650 0 0
								11000 4230 2500 0 0
								11000 4230 2000 0 0
								11000 4510 1650 0 0
								11000 4510 1500 0 0
								11000 4540 1050 0 0
								11000 4550 1000 1 0>;
				strategy_temp_normal_low =	<11000 4100 7300 0 30
								11000 4100 7000 0 15
								11000 4100 6000 0 60
								11000 4110 5250 0 160
								11000 4110 5000 0 160
								11000 4110 4500 0 0
								11000 4380 4350 0 0
								11000 4510 4200 0 0
								11000 4510 4000 0 0
								11000 4540 3500 0 0
								11000 4540 3000 0 0
								11000 4540 2500 0 0
								11000 4540 2000 0 0
								11000 4550 1500 0 0
								11000 4525 1000 1 0>;
				strategy_temp_normal_high =	<11000 4100 7300 0 30
								11000 4100 7000 0 15
								11000 4100 6000 0 60
								11000 4110 5250 0 160
								11000 4110 5000 0 160
								11000 4110 4500 0 0
								11000 4380 4350 0 0
								11000 4510 4200 0 0
								11000 4510 4000 0 0
								11000 4540 3500 0 0
								11000 4540 3000 0 0
								11000 4540 2500 0 0
								11000 4540 2000 0 0
								11000 4550 1550 0 0
								11000 4525 1000 1 0>;
				strategy_temp_warm =		<11000 4120 1950 0 0
								11000 4120 1500 0 0
								11000 4130 1000 1 0>;
			};
			strategy_soc_range_mid {
				strategy_temp_little_cold =	<11000 4130 1000 1 0>;
				strategy_temp_cool =		<11000 3980 1500 0 0
								11000 4120 1150 0 0
								11000 4130 1000 1 0>;
				strategy_temp_little_cool =	<11000 4080 2000 0 0
								11000 4230 1650 0 0
								11000 4230 1500 0 0
								11000 4420 1150 0 0
								11000 4430 1000 1 0>;
				strategy_temp_little_cool_high =	<11000 4230 2000 0 0
								11000 4510 1650 0 0
								11000 4510 1500 0 0
								11000 4540 1050 0 0
								11000 4550 1000 1 0>;
				strategy_temp_normal_low =	<11000 4540 2500 0 0
								11000 4540 2000 0 0
								11000 4550 1500 0 0
								11000 4525 1000 1 0>;
				strategy_temp_normal_high =	<11000 4540 3000 0 0
								11000 4540 2500 0 0
								11000 4540 2000 0 0
								11000 4550 1550 0 0
								11000 4525 1000 1 0>;
				strategy_temp_warm =		<11000 4130 1000 1 0>;
			};
			strategy_soc_range_mid_high {
				strategy_temp_little_cold =	<11000 4130 1000 1 0>;
				strategy_temp_cool =		<11000 4130 1000 1 0>;
				strategy_temp_little_cool =	<11000 4230 1500 0 0
								11000 4420 1150 0 0
								11000 4430 1000 1 0>;
				strategy_temp_little_cool_high =	<11000 4510 1500 0 0
								11000 4540 1050 0 0
								11000 4550 1000 1 0>;
				strategy_temp_normal_low =	<11000 4540 2000 0 0
								11000 4550 1500 0 0
								11000 4525 1000 1 0>;
				strategy_temp_normal_high =	<11000 4540 2500 0 0
								11000 4540 2000 0 0
								11000 4550 1550 0 0
								11000 4525 1000 1 0>;
				strategy_temp_warm =		<11000 4130 1000 1 0>;
			};
			strategy_soc_range_high {
				strategy_temp_little_cold =	<11000 4130 1000 1 0>;
				strategy_temp_cool =		<11000 4130 1000 1 0>;
				strategy_temp_little_cool =	<11000 4430 1000 1 0>;
				strategy_temp_little_cool_high =	<11000 4550 1000 1 0>;
				strategy_temp_normal_low =	<11000 4550 1500 0 0
								11000 4525 1000 1 0>;
				strategy_temp_normal_high =	<11000 4550 1550 0 0
								11000 4525 1000 1 0>;
				strategy_temp_warm =		<11000 4130 1000 1 0>;
			};
		};

		oplus,impedance_node {
			ufcs_input_impedance: ufcs_input_impedance {
				node_name = "ufcs_input";
				default_impedance_mohm = <0>;
				default_curr_ma = <7300>;
				current_drop_table = <
					125 10000
					130 8000
					190 5000
					250 4000
					340 3000
					380 2000
					480 0
				>;
			};
		};
	};
};

&soc {
	oplus_virtual_pps: oplus,virtual_pps {
		compatible = "oplus,virtual_pps";

		oplus,ic_type = <OPLUS_CHG_IC_VIRTUAL_PPS>;
		oplus,ic_index = <0>;
		oplus,pps_ic = <&oplus_mtk_pps>;
	};
	oplus_pps_charge: oplus,pps_charge {
		compatible = "oplus,pps_charge";
		oplus,pps_ic = <&oplus_virtual_pps>;
		oplus,cp_ic = <&oplus_virtual_cp>;
		oplus,dpdm_switch_ic = <&oplus_virtual_dpdm_switch>;

		oplus,target_vbus_mv = <11000>;
		oplus,curr_max_ma = <5000>;
		oplus,curr_max_ma_percent = <2500 /* 75% ibus */
						1000 /* 85% ibus */>;

		oplus,pps_warm_allow_vol = <4000>;
		oplus,pps_warm_allow_soc = <55>;
		oplus,pps_strategy_normal_current = <5000>;
		oplus,pps_over_high_or_low_current = <5000>;
		oplus,pps_timeout_third = <18681>;
		oplus,pps_timeout_oplus = <18681>;
		oplus,pps_ibat_over_third = <11400>;
		oplus,pps_ibat_over_oplus = <11400>;
		oplus,pps_full_cool_sw_vbat = <4130>;
		oplus,pps_full_normal_sw_vbat = <4500>;
		oplus,pps_full_normal_hw_vbat = <4540>;
		oplus,pps_full_ffc_vbat = <4500>;
		oplus,pps_full_warm_vbat = <4130>;
		oplus,pps_full_cool_sw_vbat_third = <4130>;
		oplus,pps_full_normal_sw_vbat_third= <4500>;
		oplus,pps_full_normal_hw_vbat_third = <4540>;
		oplus,pps_current_change_timeout = <100>;
		oplus,curve_strategy_name = "pps_ufcs_curve_v2";
		oplus,pps_strategy_batt_high_temp = <410 430 435 400 425 430>;
		oplus,pps_strategy_high_current = <5000 3000 2000 5000 5000 3000>;
		oplus,pps_little_cool_high_temp = <210>;
		oplus,pps_charge_strategy_soc = <0 20 35 55 75 85 90>;
		oplus,pps_charge_strategy_temp = <50 50 120 160 350 440 510>;
		oplus,pps_low_temp = <50>;
		oplus,pps_full_recheck_temp = <210>;

		oplus,pps_vfa_strategy = <&ratio2t1_vfa_strategy>;

		oplus,plc_strategy-data = <&cp_2t1_simple_strategy>;
		oplus,plc_strategy-names = "default";

		oplus,temperature_strategy_name = "cgcl";
		oplus,temperature_strategy_data = < OPLUS_STRATEGY_USE_SHELL_TEMP
							0   400 5000 1 0
							395 420 4000 2 0
							410 430 3000 3 1
							425 440 2500 4 2
							435 450 2000 4 3>;

		pps_oplus_lcf_strategy {
			oplus,temp_type = <OPLUS_STRATEGY_USE_SHELL_TEMP>;
			oplus,temp_range = <0 50 120 160 210 380 440>;

			strategy_temp_range_curves {
				strategy_temp_range_t0 =	<350 4500 0
								 325 4490 0
								 300 4480 0
								 275 4470 0
								 250 4460 1>;
				strategy_temp_range_t1 =	<950 4550 0
								 900 4545 0
								 850 4530 0
								 750 4520 0
								 650 4510 1>;
				strategy_temp_range_t2 =	<1100 4550 0
								 1050 4545 0
								 950  4530 0
								 850  4520 0
								 700  4510 1>;
				strategy_temp_range_t3 =	<1200 4550 0
								 1150 4545 0
								 1050 4530 0
								 950  4520 0
								 800  4510 1>;
				strategy_temp_range_t4 =	<2700 4550 0
								 2500 4550 0
								 2000 4545 0
								 1500 4530 0
								 1000 4515 1>;
				strategy_temp_range_t5 =	<2800 4534 0
								 2600 4531 0
								 2100 4520 0
								 1600 4505 0
								 1000 4475 1>;
			};
		};

		pps_third_lcf_strategy {
			oplus,temp_type = <OPLUS_STRATEGY_USE_SHELL_TEMP>;
			oplus,temp_range = <0 50 120 160 210 380 440>;

			strategy_temp_range_curves {
				strategy_temp_range_t0 =	<350 4500 0
								 325 4490 0
								 300 4480 0
								 275 4470 0
								 250 4460 1>;
				strategy_temp_range_t1 =	<950 4550 0
								 900 4545 0
								 850 4530 0
								 750 4520 0
								 650 4510 1>;
				strategy_temp_range_t2 =	<1100 4550 0
								 1050 4545 0
								 950  4530 0
								 850  4520 0
								 700  4510 1>;
				strategy_temp_range_t3 =	<1200 4550 0
								 1150 4545 0
								 1050 4530 0
								 950  4520 0
								 800  4510 1>;
				strategy_temp_range_t4 =	<2700 4550 0
								 2500 4550 0
								 2000 4545 0
								 1500 4530 0
								 1000 4515 1>;
				strategy_temp_range_t5 =	<2800 4534 0
								 2600 4531 0
								 2100 4520 0
								 1600 4505 0
								 1000 4475 1>;
			};
		};

		pps_charge_third_strategy {
			oplus,temp_type = <OPLUS_STRATEGY_USE_SHELL_TEMP>;
			oplus,soc_range = <0 20 35 55 75 85 90>;
			oplus,temp_range = <0 50 120 160 210 350 440 510>;

			strategy_soc_range_min {
				strategy_temp_little_cold =	<11000 4130 1000 1 0>;
				strategy_temp_cool =		<11000 3980 1650 0 0
								11000 3980 1500 0 0
								11000 4120 1150 0 0
								11000 4130 1000 1 0>;
				strategy_temp_little_cool =	<11000 4080 2650 0 0
								11000 4080 2500 0 0
								11000 4080 2000 0 0
								11000 4230 1650 0 0
								11000 4230 1500 0 0
								11000 4420 1150 0 0
								11000 4430 1000 1 0>;
				strategy_temp_little_cool_high =	<11000 4080 3350 0 0
								11000 4080 3000 0 0
								11000 4230 2650 0 0
								11000 4230 2500 0 0
								11000 4230 2000 0 0
								11000 4490 1650 0 0
								11000 4490 1500 0 0
								11000 4490 1050 0 0
								11000 4500 1000 1 0>;
				strategy_temp_normal_low =	<11000 4110 5000 0 0
								11000 4110 4500 0 0
								11000 4380 4350 0 0
								11000 4490 4200 0 0
								11000 4490 4000 0 0
								11000 4490 3500 0 0
								11000 4490 3000 0 0
								11000 4490 2500 0 0
								11000 4490 2000 0 0
								11000 4490 1500 0 0
								11000 4500 1000 1 0>;
				strategy_temp_normal_high =	<11000 4110 5000 0 0
								11000 4110 4500 0 0
								11000 4380 4350 0 0
								11000 4475 4200 0 0
								11000 4475 4000 0 0
								11000 4475 3500 0 0
								11000 4475 3000 0 0
								11000 4475 2500 0 0
								11000 4475 2000 0 0
								11000 4475 1500 0 0
								11000 4485 1000 1 0>;
				strategy_temp_warm =		<11000 4120 1950 0 0
								11000 4120 1500 0 0
								11000 4130 1000 1 0>;
			};
			strategy_soc_range_low {
				strategy_temp_little_cold =	<11000 4130 1000 1 0>;
				strategy_temp_cool =		<11000 3980 1650 0 0
								11000 3980 1500 0 0
								11000 4120 1150 0 0
								11000 4130 1000 1 0>;
				strategy_temp_little_cool =	<11000 4080 2650 0 0
								11000 4080 2500 0 0
								11000 4080 2000 0 0
								11000 4230 1650 0 0
								11000 4230 1500 0 0
								11000 4420 1150 0 0
								11000 4430 1000 1 0>;
				strategy_temp_little_cool_high =	<11000 4080 3350 0 0
								11000 4080 3000 0 0
								11000 4230 2650 0 0
								11000 4230 2500 0 0
								11000 4230 2000 0 0
								11000 4490 1650 0 0
								11000 4490 1500 0 0
								11000 4490 1050 0 0
								11000 4500 1000 1 0>;
				strategy_temp_normal_low =	<11000 4110 5000 0 0
								11000 4110 4500 0 0
								11000 4380 4350 0 0
								11000 4490 4200 0 0
								11000 4490 4000 0 0
								11000 4490 3500 0 0
								11000 4490 3000 0 0
								11000 4490 2500 0 0
								11000 4490 2000 0 0
								11000 4490 1500 0 0
								11000 4500 1000 1 0>;
				strategy_temp_normal_high =	<11000 4110 5000 0 0
								11000 4110 4500 0 0
								11000 4380 4350 0 0
								11000 4475 4200 0 0
								11000 4475 4000 0 0
								11000 4475 3500 0 0
								11000 4475 3000 0 0
								11000 4475 2500 0 0
								11000 4475 2000 0 0
								11000 4475 1500 0 0
								11000 4485 1000 1 0>;
				strategy_temp_warm =		<11000 4120 1950 0 0
								11000 4120 1500 0 0
								11000 4130 1000 1 0>;
			};
			strategy_soc_range_mid_low {
				strategy_temp_little_cold =	<11000 4130 1000 1 0>;
				strategy_temp_cool =		<11000 3980 1650 0 0
								11000 3980 1500 0 0
								11000 4120 1150 0 0
								11000 4130 1000 1 0>;
				strategy_temp_little_cool =	<11000 4080 2650 0 0
								11000 4080 2500 0 0
								11000 4080 2000 0 0
								11000 4230 1650 0 0
								11000 4230 1500 0 0
								11000 4420 1150 0 0
								11000 4430 1000 1 0>;
				strategy_temp_little_cool_high =	<11000 4080 3000 0 0
								11000 4230 2650 0 0
								11000 4230 2500 0 0
								11000 4230 2000 0 0
								11000 4490 1650 0 0
								11000 4490 1500 0 0
								11000 4490 1050 0 0
								11000 4500 1000 1 0>;
				strategy_temp_normal_low =	<11000 4110 5000 0 0
								11000 4110 4500 0 0
								11000 4380 4350 0 0
								11000 4490 4200 0 0
								11000 4490 4000 0 0
								11000 4490 3500 0 0
								11000 4490 3000 0 0
								11000 4490 2500 0 0
								11000 4490 2000 0 0
								11000 4490 1500 0 0
								11000 4500 1000 1 0>;
				strategy_temp_normal_high =	<11000 4110 5000 0 0
								11000 4110 4500 0 0
								11000 4380 4350 0 0
								11000 4475 4200 0 0
								11000 4475 4000 0 0
								11000 4475 3500 0 0
								11000 4475 3000 0 0
								11000 4475 2500 0 0
								11000 4475 2000 0 0
								11000 4475 1500 0 0
								11000 4485 1000 1 0>;
				strategy_temp_warm =		<11000 4120 1950 0 0
								11000 4120 1500 0 0
								11000 4130 1000 1 0>;
			};
			strategy_soc_range_mid {
				strategy_temp_little_cold =	<11000 4130 1000 1 0>;
				strategy_temp_cool =		<11000 3980 1500 0 0
								11000 4120 1150 0 0
								11000 4130 1000 1 0>;
				strategy_temp_little_cool =	<11000 4080 2000 0 0
								11000 4230 1650 0 0
								11000 4230 1500 0 0
								11000 4420 1150 0 0
								11000 4430 1000 1 0>;
				strategy_temp_little_cool_high =	<11000 4230 2000 0 0
								11000 4490 1650 0 0
								11000 4490 1500 0 0
								11000 4490 1050 0 0
								11000 4500 1000 1 0>;
				strategy_temp_normal_low =	<11000 4490 2000 0 0
								11000 4490 1500 0 0
								11000 4500 1000 1 0>;
				strategy_temp_normal_high =	<11000 4475 2500 0 0
								11000 4475 2000 0 0
								11000 4475 1500 0 0
								11000 4485 1000 1 0>;
				strategy_temp_warm =		<11000 4130 1000 1 0>;
			};
			strategy_soc_range_mid_high {
				strategy_temp_little_cold =	<11000 4130 1000 1 0>;
				strategy_temp_cool =		<11000 4130 1000 1 0>;
				strategy_temp_little_cool =	<11000 4230 1500 0 0
								11000 4420 1150 0 0
								11000 4430 1000 1 0>;
				strategy_temp_little_cool_high =	<11000 4490 1500 0 0
								11000 4490 1050 0 0
								11000 4500 1000 1 0>;
				strategy_temp_normal_low =	<11000 4490 2000 0 0
								11000 4490 1500 0 0
								11000 4500 1000 1 0>;
				strategy_temp_normal_high =	<11000 4475 2000 0 0
								11000 4475 1500 0 0
								11000 4485 1000 1 0>;
				strategy_temp_warm =		<11000 4130 1000 1 0>;
			};
			strategy_soc_range_high {
				strategy_temp_little_cold =	<11000 4130 1000 1 0>;
				strategy_temp_cool =		<11000 4130 1000 1 0>;
				strategy_temp_little_cool =	<11000 4430 1000 1 0>;
				strategy_temp_little_cool_high =	<11000 4500 1000 1 0>;
				strategy_temp_normal_low =	<11000 4500 1000 1 0>;
				strategy_temp_normal_high =	<11000 4475 1500 0 0
								11000 4485 1000 1 0>;
				strategy_temp_warm =		<11000 4130 1000 1 0>;
			};
		};

		pps_charge_oplus_strategy {
			oplus,temp_type = <OPLUS_STRATEGY_USE_SHELL_TEMP>;
			oplus,soc_range = <0 20 35 55 75 85 90>;
			oplus,temp_range = <0 50 120 160 210 350 440 500>;

			strategy_soc_range_min {
				strategy_temp_little_cold =	<11000 4130 1000 1 0>;
				strategy_temp_cool =		<11000 3980 1600 0 0
								11000 3980 1500 0 0
								11000 4120 1150 0 0
								11000 4130 1000 1 0>;
				strategy_temp_little_cool =	<11000 4080 2650 0 0
								11000 4080 2500 0 0
								11000 4080 2000 0 0
								11000 4230 1650 0 0
								11000 4230 1500 0 0
								11000 4420 1150 0 0
								11000 4430 1000 1 0>;
				strategy_temp_little_cool_high =	<11000 4080 3350 0 0
								11000 4080 3000 0 0
								11000 4230 2650 0 0
								11000 4230 2500 0 0
								11000 4230 2000 0 0
								11000 4510 1650 0 0
								11000 4510 1500 0 0
								11000 4540 1050 0 0
								11000 4550 1000 1 0>;
				strategy_temp_normal_low =	<11000 4110 5000 0 0
								11000 4110 4500 0 0
								11000 4380 4350 0 0
								11000 4490 4200 0 0
								11000 4490 4000 0 0
								11000 4490 3500 0 0
								11000 4490 3000 0 0
								11000 4490 2500 0 0
								11000 4490 2000 0 0
								11000 4490 1500 0 0
								11000 4500 1000 1 0>;
				strategy_temp_normal_high =	<11000 4110 5000 0 0
								11000 4110 4500 0 0
								11000 4380 4350 0 0
								11000 4475 4200 0 0
								11000 4475 4000 0 0
								11000 4475 3500 0 0
								11000 4475 3000 0 0
								11000 4475 2500 0 0
								11000 4475 2000 0 0
								11000 4475 1500 0 0
								11000 4485 1000 1 0>;
				strategy_temp_warm =		<11000 4120 2000 0 0
								11000 4120 1500 0 0
								11000 4130 1000 1 0>;
			};
			strategy_soc_range_low {
				strategy_temp_little_cold =	<11000 4130 1000 1 0>;
				strategy_temp_cool =		<11000 3980 1600 0 0
								11000 3980 1500 0 0
								11000 4120 1150 0 0
								11000 4130 1000 1 0>;
				strategy_temp_little_cool =	<11000 4080 2650 0 0
								11000 4080 2500 0 0
								11000 4080 2000 0 0
								11000 4230 1650 0 0
								11000 4230 1500 0 0
								11000 4420 1150 0 0
								11000 4430 1000 1 0>;
				strategy_temp_little_cool_high =	<11000 4080 3350 0 0
								11000 4080 3000 0 0
								11000 4230 2650 0 0
								11000 4230 2500 0 0
								11000 4230 2000 0 0
								11000 4490 1650 0 0
								11000 4490 1500 0 0
								11000 4490 1050 0 0
								11000 4500 1000 1 0>;
				strategy_temp_normal_low =	<11000 4110 5000 0 0
								11000 4110 4500 0 0
								11000 4380 4350 0 0
								11000 4490 4200 0 0
								11000 4490 4000 0 0
								11000 4490 3500 0 0
								11000 4490 3000 0 0
								11000 4490 2500 0 0
								11000 4490 2000 0 0
								11000 4490 1500 0 0
								11000 4500 1000 1 0>;
				strategy_temp_normal_high =	<11000 4110 5000 0 0
								11000 4110 4500 0 0
								11000 4380 4350 0 0
								11000 4475 4200 0 0
								11000 4475 4000 0 0
								11000 4475 3500 0 0
								11000 4475 3000 0 0
								11000 4475 2500 0 0
								11000 4475 2000 0 0
								11000 4475 1500 0 0
								11000 4485 1000 1 0>;
				strategy_temp_warm =		<11000 4120 2000 0 0
								11000 4120 1500 0 0
								11000 4130 1000 1 0>;
			};
			strategy_soc_range_mid_low {
				strategy_temp_little_cold =	<11000 4130 1000 1 0>;
				strategy_temp_cool =		<11000 3980 1600 0 0
								11000 3980 1500 0 0
								11000 4120 1150 0 0
								11000 4130 1000 1 0>;
				strategy_temp_little_cool =	<11000 4080 2650 0 0
								11000 4080 2500 0 0
								11000 4080 2000 0 0
								11000 4230 1650 0 0
								11000 4230 1500 0 0
								11000 4420 1150 0 0
								11000 4430 1000 1 0>;
				strategy_temp_little_cool_high =	<11000 4080 3350 0 0
								11000 4080 3000 0 0
								11000 4230 2650 0 0
								11000 4230 2500 0 0
								11000 4230 2000 0 0
								11000 4490 1650 0 0
								11000 4490 1500 0 0
								11000 4490 1050 0 0
								11000 4500 1000 1 0>;
				strategy_temp_normal_low =	<11000 4110 5000 0 0
								11000 4110 4500 0 0
								11000 4380 4350 0 0
								11000 4490 4200 0 0
								11000 4490 4000 0 0
								11000 4490 3500 0 0
								11000 4490 3000 0 0
								11000 4490 2500 0 0
								11000 4490 2000 0 0
								11000 4490 1500 0 0
								11000 4500 1000 1 0>;
				strategy_temp_normal_high =	<11000 4110 5000 0 0
								11000 4110 4500 0 0
								11000 4380 4350 0 0
								11000 4475 4200 0 0
								11000 4475 4000 0 0
								11000 4475 3500 0 0
								11000 4475 3000 0 0
								11000 4475 2500 0 0
								11000 4475 2000 0 0
								11000 4475 1500 0 0
								11000 4485 1000 1 0>;
				strategy_temp_warm =		<11000 4120 2000 0 0
								11000 4120 1500 0 0
								11000 4130 1000 1 0>;
			};
			strategy_soc_range_mid {
				strategy_temp_little_cold =	<11000 4130 1000 1 0>;
				strategy_temp_cool =		<11000 3980 1500 0 0
								11000 4120 1150 0 0
								11000 4130 1000 1 0>;
				strategy_temp_little_cool =	<11000 4080 2000 0 0
								11000 4230 1650 0 0
								11000 4230 1500 0 0
								11000 4420 1150 0 0
								11000 4430 1000 1 0>;
				strategy_temp_little_cool_high =	<11000 4230 2000 0 0
								11000 4490 1650 0 0
								11000 4490 1500 0 0
								11000 4490 1050 0 0
								11000 4500 1000 1 0>;
				strategy_temp_normal_low =	<11000 4490 2000 0 0
								11000 4490 1500 0 0
								11000 4500 1000 1 0>;
				strategy_temp_normal_high =	<11000 4475 2500 0 0
								11000 4475 2000 0 0
								11000 4475 1500 0 0
								11000 4485 1000 1 0>;
				strategy_temp_warm =		<11000 4130 1000 1 0>;
			};
			strategy_soc_range_mid_high {
				strategy_temp_little_cold =	<11000 4130 1000 1 0>;
				strategy_temp_cool =		<11000 4130 1000 1 0>;
				strategy_temp_little_cool =	<11000 4430 1000 1 0>;
				strategy_temp_little_cool_high =	<11000 4500 1000 1 0>;
				strategy_temp_normal_low =	<11000 4490 1500 0 0
								11000 4500 1000 1 0>;
				strategy_temp_normal_high =	<11000 4475 1500 0 0
								11000 4485 1000 1 0>;
				strategy_temp_warm =		<11000 4130 1000 1 0>;
			};
			strategy_soc_range_high {
				strategy_temp_little_cold =	<11000 4130 1000 1 0>;
				strategy_temp_cool =		<11000 4130 1000 1 0>;
				strategy_temp_little_cool =	<11000 4430 1000 1 0>;
				strategy_temp_little_cool_high =	<11000 4500 1000 1 0>;
				strategy_temp_normal_low =	<11000 4500 1000 1 0>;
				strategy_temp_normal_high =	<11000 4475 1500 0 0
								11000 4485 1000 1 0>;
				strategy_temp_warm =		<11000 4130 1000 1 0>;
			};
		};
	};
};

&soc {
	oplus_chg_plc: oplus,plc_charge {
		compatible = "oplus,plc_charge";
		oplus,plc_soc = <90>;
		oplus,plc_support_timeout;
		oplus,plc_strategy-data = <&buck_simple_strategy>;
		oplus,plc_strategy-names = "default";

		oplus_ufcs_step_strategy: oplus_ufcs_step_strategy {
			oplus,strategy_type = <PLC_STRATEGY_STEP>;
		};

		cp_2t1_simple_strategy: cp_2t1_simple_strategy {
			oplus,strategy_type = <PLC_STRATEGY_SIMPLE>;
			oplus,strategy_data {
				strategy_curr_ma = <1000 1500>;
			};
		};

		cp_1t1_simple_strategy: cp_1t1_simple_strategy {
			oplus,strategy_type = <PLC_STRATEGY_SIMPLE>;
			oplus,strategy_data {
				strategy_curr_ma = <2000 3000>;
			};
		};

		buck_simple_strategy: buck_simple_strategy {
			oplus,strategy_type = <PLC_STRATEGY_SIMPLE>;
		};
	};
};

/* chagrge end */
